AUTOSAR XML (schema 00046)
package /MICROSAR/Dcm_swc
  4 x mode declaration group, all with category=EXPLICIT_ORDER:
    DcmControlDtcSetting: initial-mode=ENABLEDTCSETTING, on-transition-value=2
      mode ENABLEDTCSETTING: value=0
      mode DISABLEDTCSETTING: value=1
    DcmEcuReset: initial-mode=NONE, on-transition-value=7
      7 x mode:
        NONE: value=0
        HARD: value=1
        KEYONOFF: value=2
        SOFT: value=3
        JUMPTOBOOTLOADER: value=4
        JUMPTOSYSSUPPLIERBOOTLOADER: value=5
        EXECUTE: value=6
    DcmDiagnosticSessionControl: initial-mode=DEFAULT_SESSION, on-transition-value=255
      mode DEFAULT_SESSION: value=1
      mode PROGRAMMING_SESSION: value=2
      mode EXTENDED_SESSION: value=3
    DcmCommunicationControl: initial-mode=DCM_ENABLE_RX_TX_NORM, on-transition-value=12
      12 x mode:
        DCM_ENABLE_RX_TX_NORM: value=0
        DCM_ENABLE_RX_DISABLE_TX_NORM: value=1
        DCM_DISABLE_RX_ENABLE_TX_NORM: value=2
        DCM_DISABLE_RX_TX_NORMAL: value=3
        DCM_ENABLE_RX_TX_NM: value=4
        DCM_ENABLE_RX_DISABLE_TX_NM: value=5
        DCM_DISABLE_RX_ENABLE_TX_NM: value=6
        DCM_DISABLE_RX_TX_NM: value=7
        DCM_ENABLE_RX_TX_NORM_NM: value=8
        DCM_ENABLE_RX_DISABLE_TX_NORM_NM: value=9
        DCM_DISABLE_RX_ENABLE_TX_NORM_NM: value=10
        DCM_DISABLE_RX_TX_NORM_NM: value=11
  data type mapping set DcmMappingSet  # Contains mapping for ModeDeclarationGroups which are provided by Dcm.
    mode-request-type-maps:
      implementation-data-type=Dcm_ControlDtcSettingType, mode-group=DcmControlDtcSetting
      implementation-data-type=Dcm_EcuResetType, mode-group=DcmEcuReset
      implementation-data-type=Dcm_DiagnosticSessionControlType, mode-group=DcmDiagnosticSessionControl
      implementation-data-type=Dcm_CommunicationModeType, mode-group=DcmCommunicationControl
package /MICROSAR/Dcm_swc/DataTypes
  18 x impl type:
    Dcm_ConfirmationStatusType: compu {0=DCM_RES_POS_OK, 1=DCM_RES_POS_NOT_OK, 2=DCM_RES_NEG_OK, 3=DCM_RES_NEG_NOT_OK}, range raw 0..3, implementation-data-type=uint8
    Dcm_OpStatusType: compu {0=DCM_INITIAL, 1=DCM_PENDING, 2=DCM_CANCEL, 3=DCM_FORCE_RCRRP_OK, 64=DCM_FORCE_RCRRP_NOT_OK}, range raw 0..64, implementation-data-type=uint8
    Dcm_NegativeResponseCodeType:
      compu {0=DCM_E_POSITIVERESPONSE, 16=DCM_E_GENERALREJECT, 17=DCM_E_SERVICENOTSUPPORTED, 18=DCM_E_SUBFUNCTIONNOTSUPPORTED, 19=DCM_E_INCORRECTMESSAGELENGTHORINVALIDFORMAT, 20=DCM_E_RESPONSETOOLONG, 33=DCM_E_BUSYREPEATREQUEST, 34=DCM_E_CONDITIONSNOTCORRECT, 36=DCM_E_REQUESTSEQUENCEERROR, 37=DCM_E_NORESPONSEFROMSUBNETCOMPONENT, 38=DCM_E_FAILUREPREVENTSEXECUTIONOFREQUESTEDACTION, 49=DCM_E_REQUESTOUTOFRANGE, 51=DCM_E_SECURITYACCESSDENIED, 53=DCM_E_INVALIDKEY, 54=DCM_E_EXCEEDNUMBEROFATTEMPTS, 55=DCM_E_REQUIREDTIMEDELAYNOTEXPIRED, 112=DCM_E_UPLOADDOWNLOADNOTACCEPTED, 113=DCM_E_TRANSFERDATASUSPENDED, 114=DCM_E_GENERALPROGRAMMINGFAILURE, 115=DCM_E_WRONGBLOCKSEQUENCECOUNTER, 120=DCM_E_REQUESTCORRECTLYRECEIVEDRESPONSEPENDING, 126=DCM_E_SUBFUNCTIONNOTSUPPORTEDINACTIVESESSION, 127=DCM_E_SERVICENOTSUPPORTEDINACTIVESESSION, 129=DCM_E_RPMTOOHIGH, 130=DCM_E_RPMTOOLOW, 131=DCM_E_ENGINEISRUNNING, 132=DCM_E_ENGINEISNOTRUNNING, 133=DCM_E_ENGINERUNTIMETOOLOW, 134=DCM_E_TEMPERATURETOOHIGH, 135=DCM_E_TEMPERATURETOOLOW, 136=DCM_E_VEHICLESPEEDTOOHIGH, 137=DCM_E_VEHICLESPEEDTOOLOW, 138=DCM_E_THROTTLE_PEDALTOOHIGH, 139=DCM_E_THROTTLE_PEDALTOOLOW, 140=DCM_E_TRANSMISSIONRANGENOTINNEUTRAL, 141=DCM_E_TRANSMISSIONRANGENOTINGEAR, 143=DCM_E_BRAKESWITCH_NOTCLOSED, 144=DCM_E_SHIFTERLEVERNOTINPARK, 145=DCM_E_TORQUECONVERTERCLUTCHLOCKED, 146=DCM_E_VOLTAGETOOHIGH, 147=DCM_E_VOLTAGETOOLOW, 240..249=DCM_E_VMSCNC_0..DCM_E_VMSCNC_9, 250=DCM_E_VMSCNC_A, 251=DCM_E_VMSCNC_B, 252=DCM_E_VMSCNC_C, 253=DCM_E_VMSCNC_D, 254=DCM_E_VMSCNC_E}
      range raw 0..254
      implementation-data-type=uint8
    Dcm_ProtocolType: compu {0=DCM_OBD_ON_CAN, 1=DCM_OBD_ON_FLEXRAY, 2=DCM_OBD_ON_IP, 3=DCM_UDS_ON_CAN, 4=DCM_UDS_ON_FLEXRAY, 5=DCM_UDS_ON_IP, 12=DCM_NO_ACTIVE_PROTOCOL, 240..254=DCM_SUPPLIER_1..DCM_SUPPLIER_15}, range raw 0..254, implementation-data-type=uint8
    Dcm_RequestKindType: compu {0=DCM_REQ_KIND_NONE, 1=DCM_REQ_KIND_EXTERNAL, 2=DCM_REQ_KIND_ROE}, range raw 0..2, implementation-data-type=uint8
    Dcm_SesCtrlType: compu {1=DCM_DEFAULT_SESSION, 2=DCM_PROGRAMMING_SESSION, 3=DCM_EXTENDED_DIAGNOSTIC_SESSION}, range raw 0..3, implementation-data-type=uint8
    Dcm_ControlDtcSettingType: compu {0=DCM_ENUM_ENABLEDTCSETTING, 1=DCM_ENUM_DISABLEDTCSETTING}, range raw 0..255, implementation-data-type=uint8
    Dcm_EcuResetType: compu {0=DCM_ENUM_NONE, 1=DCM_ENUM_HARD, 2=DCM_ENUM_KEYONOFF, 3=DCM_ENUM_SOFT, 4=DCM_ENUM_JUMPTOBOOTLOADER, 5=DCM_ENUM_JUMPTOSYSSUPPLIERBOOTLOADER, 6=DCM_ENUM_EXECUTE}, range raw 0..255, implementation-data-type=uint8
    Dcm_DiagnosticSessionControlType: compu {1=DCM_ENUM_DEFAULT_SESSION, 2=DCM_ENUM_PROGRAMMING_SESSION, 3=DCM_ENUM_EXTENDED_SESSION}, range raw 0..255, implementation-data-type=uint8
    Dcm_CommunicationModeType:
      compu {0=DCM_ENABLE_RX_TX_NORM, 1=DCM_ENABLE_RX_DISABLE_TX_NORM, 2=DCM_DISABLE_RX_ENABLE_TX_NORM, 3=DCM_DISABLE_RX_TX_NORMAL, 4=DCM_ENABLE_RX_TX_NM, 5=DCM_ENABLE_RX_DISABLE_TX_NM, 6=DCM_DISABLE_RX_ENABLE_TX_NM, 7=DCM_DISABLE_RX_TX_NM, 8=DCM_ENABLE_RX_TX_NORM_NM, 9=DCM_ENABLE_RX_DISABLE_TX_NORM_NM, 10=DCM_DISABLE_RX_ENABLE_TX_NORM_NM, 11=DCM_DISABLE_RX_TX_NORM_NM}
      range raw 0..255
      implementation-data-type=uint8
    Dcm_Data1ByteType: category=ARRAY, sw-calibration-access=READ-ONLY
      element Dcm_Data1ByteTypeElement: array-size=1, array-size-semantics=FIXED-SIZE, implementation-data-type=uint8
    Dcm_SecLevelType: compu {0=DCM_SEC_LEV_LOCKED, 1=DCM_SEC_LEV_L1}, range raw 0..1, implementation-data-type=uint8
    Dcm_Data4ByteType: category=ARRAY, sw-calibration-access=READ-ONLY
      element Dcm_Data4ByteTypeElement: array-size=4, array-size-semantics=FIXED-SIZE, implementation-data-type=uint8
    Dcm_Data2ByteType: category=ARRAY, sw-calibration-access=READ-ONLY
      element Dcm_Data2ByteTypeElement: array-size=2, array-size-semantics=FIXED-SIZE, implementation-data-type=uint8
    Dcm_Data13ByteType: category=ARRAY, sw-calibration-access=READ-ONLY
      element Dcm_Data13ByteTypeElement: array-size=13, array-size-semantics=FIXED-SIZE, implementation-data-type=uint8
    Dcm_Data17ByteType: category=ARRAY, sw-calibration-access=READ-ONLY
      element Dcm_Data17ByteTypeElement: array-size=17, array-size-semantics=FIXED-SIZE, implementation-data-type=uint8
    Dcm_Data5ByteType: category=ARRAY, sw-calibration-access=READ-ONLY
      element Dcm_Data5ByteTypeElement: array-size=5, array-size-semantics=FIXED-SIZE, implementation-data-type=uint8
    Dcm_Data8ByteType: category=ARRAY, sw-calibration-access=READ-ONLY
      element Dcm_Data8ByteTypeElement: array-size=8, array-size-semantics=FIXED-SIZE, implementation-data-type=uint8
package /MICROSAR/Dcm_swc/Interfaces
  mode switch interface DcmControlDtcSetting: is-service=true, service-kind=DIAGNOSTIC-COMMUNICATION-MANAGER
    mode group DcmControlDtcSetting: type=DcmControlDtcSetting
  mode switch interface DcmEcuReset: is-service=true, service-kind=DIAGNOSTIC-COMMUNICATION-MANAGER
    mode group DcmEcuReset: type=DcmEcuReset
  mode switch interface DcmDiagnosticSessionControl: is-service=true, service-kind=DIAGNOSTIC-COMMUNICATION-MANAGER
    mode group DcmDiagnosticSessionControl: type=DcmDiagnosticSessionControl
  client server interface DCMServices: is-service=true, service-kind=DIAGNOSTIC-COMMUNICATION-MANAGER
    6 x operation:
      GetActiveProtocol: possible-error=E_OK
        arg ActiveProtocol: type=Dcm_ProtocolType, direction=OUT
      GetSesCtrlType: possible-error=E_OK
        arg SesCtrlType: type=Dcm_SesCtrlType, direction=OUT
      ResetToDefaultSession: possible-error=E_OK
      SetActiveDiagnostic: possible-error=E_OK
        arg active: type=boolean, direction=IN
      GetRequestKind: possible-error=DCMServices/E_NOT_OK
        arg TesterSourceAddress: type=uint16, direction=IN
        arg RequestKind: type=Dcm_RequestKindType, direction=OUT
      GetSecurityLevel: possible-error=E_OK
        arg SecLevel: type=Dcm_SecLevelType, direction=OUT
    error E_OK: error-code=0
    error E_NOT_OK: error-code=1
  client server interface RoutineServices_ECU_Check: is-service=true, service-kind=DIAGNOSTIC-COMMUNICATION-MANAGER
    operation Start: possible-error=[RoutineServices_ECU_Check/E_NOT_OK, RoutineServices_ECU_Check/DCM_E_PENDING, DCM_E_FORCE_RCRRP]
      4 x arg:
        In_Start_ECU_Check: type=uint8, direction=IN
        OpStatus: type=Dcm_OpStatusType, direction=IN
        Out_ECU_Check_is_in_progress: type=uint8, direction=OUT
        ErrorCode: type=Dcm_NegativeResponseCodeType, direction=OUT
    operation RequestResults: possible-error=[RoutineServices_ECU_Check/E_NOT_OK, RoutineServices_ECU_Check/DCM_E_PENDING, DCM_E_FORCE_RCRRP]
      arg OpStatus: type=Dcm_OpStatusType, direction=IN
      arg Out_ECU_Check_status: type=uint8, direction=OUT
      arg ErrorCode: type=Dcm_NegativeResponseCodeType, direction=OUT
    error E_NOT_OK: error-code=1
    error DCM_E_PENDING: error-code=10
    error DCM_E_FORCE_RCRRP: error-code=12
  client server interface DataServices_Braking_Brake_Pedal: is-service=true, service-kind=DIAGNOSTIC-COMMUNICATION-MANAGER
    operation ReadData: possible-error=[DataServices_Braking_Brake_Pedal/E_NOT_OK, DataServices_Braking_Brake_Pedal/DCM_E_PENDING]
      arg OpStatus: type=Dcm_OpStatusType, direction=IN
      arg Data: type=Dcm_Data1ByteType, direction=OUT
    operation ConditionCheckRead: possible-error=[DataServices_Braking_Brake_Pedal/E_NOT_OK, DataServices_Braking_Brake_Pedal/DCM_E_PENDING]
      arg OpStatus: type=Dcm_OpStatusType, direction=IN
      arg ErrorCode: type=Dcm_NegativeResponseCodeType, direction=OUT
    error E_NOT_OK: error-code=1
    error DCM_E_PENDING: error-code=10
  mode switch interface DcmCommunicationControl_ComMConf_ComMChannel_CN_DBCNetWork_05d62413: is-service=true, service-kind=DIAGNOSTIC-COMMUNICATION-MANAGER
    mode group DcmCommunicationControl_ComMConf_ComMChannel_CN_DBCNetWork_05d62413: type=DcmCommunicationControl
  58 x client server interface, all with is-service=true, service-kind=DIAGNOSTIC-COMMUNICATION-MANAGER:
    SecurityAccess_UnlockedL1
      operation GetSeed: possible-error=[SecurityAccess_UnlockedL1/E_NOT_OK, SecurityAccess_UnlockedL1/DCM_E_PENDING]
        arg OpStatus: type=Dcm_OpStatusType, direction=IN
        arg Seed: type=Dcm_Data4ByteType, direction=OUT
        arg ErrorCode: type=Dcm_NegativeResponseCodeType, direction=OUT
      operation CompareKey: possible-error=[SecurityAccess_UnlockedL1/E_NOT_OK, SecurityAccess_UnlockedL1/DCM_E_PENDING, DCM_E_COMPARE_KEY_FAILED]
        arg Key: type=Dcm_Data4ByteType, direction=IN
        arg OpStatus: type=Dcm_OpStatusType, direction=IN
        arg ErrorCode: type=Dcm_NegativeResponseCodeType, direction=OUT
      error E_NOT_OK: error-code=1
      error DCM_E_PENDING: error-code=10
      error DCM_E_COMPARE_KEY_FAILED: error-code=11
    DataServices_Braking_Valve_Status_RR
      operation ReadData: possible-error=[DataServices_Braking_Valve_Status_RR/E_NOT_OK, DataServices_Braking_Valve_Status_RR/DCM_E_PENDING]
        arg OpStatus: type=Dcm_OpStatusType, direction=IN
        arg Data: type=Dcm_Data1ByteType, direction=OUT
      operation ConditionCheckRead: possible-error=[DataServices_Braking_Valve_Status_RR/E_NOT_OK, DataServices_Braking_Valve_Status_RR/DCM_E_PENDING]
        arg OpStatus: type=Dcm_OpStatusType, direction=IN
        arg ErrorCode: type=Dcm_NegativeResponseCodeType, direction=OUT
      error E_NOT_OK: error-code=1
      error DCM_E_PENDING: error-code=10
    DataServices_Braking_Valve_Status_FR
      operation ReadData: possible-error=[DataServices_Braking_Valve_Status_FR/E_NOT_OK, DataServices_Braking_Valve_Status_FR/DCM_E_PENDING]
        arg OpStatus: type=Dcm_OpStatusType, direction=IN
        arg Data: type=Dcm_Data1ByteType, direction=OUT
      operation ConditionCheckRead: possible-error=[DataServices_Braking_Valve_Status_FR/E_NOT_OK, DataServices_Braking_Valve_Status_FR/DCM_E_PENDING]
        arg OpStatus: type=Dcm_OpStatusType, direction=IN
        arg ErrorCode: type=Dcm_NegativeResponseCodeType, direction=OUT
      error E_NOT_OK: error-code=1
      error DCM_E_PENDING: error-code=10
    DataServices_Braking_Status_Hydraulic_Pump
      operation ReadData: possible-error=[DataServices_Braking_Status_Hydraulic_Pump/E_NOT_OK, DataServices_Braking_Status_Hydraulic_Pump/DCM_E_PENDING]
        arg OpStatus: type=Dcm_OpStatusType, direction=IN
        arg Data: type=Dcm_Data1ByteType, direction=OUT
      operation ConditionCheckRead: possible-error=[DataServices_Braking_Status_Hydraulic_Pump/E_NOT_OK, DataServices_Braking_Status_Hydraulic_Pump/DCM_E_PENDING]
        arg OpStatus: type=Dcm_OpStatusType, direction=IN
        arg ErrorCode: type=Dcm_NegativeResponseCodeType, direction=OUT
      error E_NOT_OK: error-code=1
      error DCM_E_PENDING: error-code=10
    DataServices_Braking_Brake_Pressure
      operation ReadData: possible-error=[DataServices_Braking_Brake_Pressure/E_NOT_OK, DataServices_Braking_Brake_Pressure/DCM_E_PENDING]
        arg OpStatus: type=Dcm_OpStatusType, direction=IN
        arg Data: type=Dcm_Data1ByteType, direction=OUT
      operation ConditionCheckRead: possible-error=[DataServices_Braking_Brake_Pressure/E_NOT_OK, DataServices_Braking_Brake_Pressure/DCM_E_PENDING]
        arg OpStatus: type=Dcm_OpStatusType, direction=IN
        arg ErrorCode: type=Dcm_NegativeResponseCodeType, direction=OUT
      error E_NOT_OK: error-code=1
      error DCM_E_PENDING: error-code=10
    DataServices_Braking_Valve_Status_RL
      operation ReadData: possible-error=[DataServices_Braking_Valve_Status_RL/E_NOT_OK, DataServices_Braking_Valve_Status_RL/DCM_E_PENDING]
        arg OpStatus: type=Dcm_OpStatusType, direction=IN
        arg Data: type=Dcm_Data1ByteType, direction=OUT
      operation ConditionCheckRead: possible-error=[DataServices_Braking_Valve_Status_RL/E_NOT_OK, DataServices_Braking_Valve_Status_RL/DCM_E_PENDING]
        arg OpStatus: type=Dcm_OpStatusType, direction=IN
        arg ErrorCode: type=Dcm_NegativeResponseCodeType, direction=OUT
      error E_NOT_OK: error-code=1
      error DCM_E_PENDING: error-code=10
    DataServices_Braking_Valve_Status_FL
      operation ReadData: possible-error=[DataServices_Braking_Valve_Status_FL/E_NOT_OK, DataServices_Braking_Valve_Status_FL/DCM_E_PENDING]
        arg OpStatus: type=Dcm_OpStatusType, direction=IN
        arg Data: type=Dcm_Data1ByteType, direction=OUT
      operation ConditionCheckRead: possible-error=[DataServices_Braking_Valve_Status_FL/E_NOT_OK, DataServices_Braking_Valve_Status_FL/DCM_E_PENDING]
        arg OpStatus: type=Dcm_OpStatusType, direction=IN
        arg ErrorCode: type=Dcm_NegativeResponseCodeType, direction=OUT
      error E_NOT_OK: error-code=1
      error DCM_E_PENDING: error-code=10
    DataServices_Hydro_Unit_Valve_Status_RR
      operation ReadData: possible-error=[DataServices_Hydro_Unit_Valve_Status_RR/E_NOT_OK, DataServices_Hydro_Unit_Valve_Status_RR/DCM_E_PENDING]
        arg OpStatus: type=Dcm_OpStatusType, direction=IN
        arg Data: type=Dcm_Data1ByteType, direction=OUT
      operation ConditionCheckRead: possible-error=[DataServices_Hydro_Unit_Valve_Status_RR/E_NOT_OK, DataServices_Hydro_Unit_Valve_Status_RR/DCM_E_PENDING]
        arg OpStatus: type=Dcm_OpStatusType, direction=IN
        arg ErrorCode: type=Dcm_NegativeResponseCodeType, direction=OUT
      error E_NOT_OK: error-code=1
      error DCM_E_PENDING: error-code=10
    DataServices_Hydro_Unit_Valve_Voltage_FR
      operation ReadData: possible-error=[DataServices_Hydro_Unit_Valve_Voltage_FR/E_NOT_OK, DataServices_Hydro_Unit_Valve_Voltage_FR/DCM_E_PENDING]
        arg OpStatus: type=Dcm_OpStatusType, direction=IN
        arg Data: type=Dcm_Data1ByteType, direction=OUT
      operation ConditionCheckRead: possible-error=[DataServices_Hydro_Unit_Valve_Voltage_FR/E_NOT_OK, DataServices_Hydro_Unit_Valve_Voltage_FR/DCM_E_PENDING]
        arg OpStatus: type=Dcm_OpStatusType, direction=IN
        arg ErrorCode: type=Dcm_NegativeResponseCodeType, direction=OUT
      error E_NOT_OK: error-code=1
      error DCM_E_PENDING: error-code=10
    DataServices_Hydro_Unit_Valve_Status_FR
      operation ReadData: possible-error=[DataServices_Hydro_Unit_Valve_Status_FR/E_NOT_OK, DataServices_Hydro_Unit_Valve_Status_FR/DCM_E_PENDING]
        arg OpStatus: type=Dcm_OpStatusType, direction=IN
        arg Data: type=Dcm_Data1ByteType, direction=OUT
      operation ConditionCheckRead: possible-error=[DataServices_Hydro_Unit_Valve_Status_FR/E_NOT_OK, DataServices_Hydro_Unit_Valve_Status_FR/DCM_E_PENDING]
        arg OpStatus: type=Dcm_OpStatusType, direction=IN
        arg ErrorCode: type=Dcm_NegativeResponseCodeType, direction=OUT
      error E_NOT_OK: error-code=1
      error DCM_E_PENDING: error-code=10
    DataServices_Hydro_Unit_Valve_Voltage_RL
      operation ReadData: possible-error=[DataServices_Hydro_Unit_Valve_Voltage_RL/E_NOT_OK, DataServices_Hydro_Unit_Valve_Voltage_RL/DCM_E_PENDING]
        arg OpStatus: type=Dcm_OpStatusType, direction=IN
        arg Data: type=Dcm_Data1ByteType, direction=OUT
      operation ConditionCheckRead: possible-error=[DataServices_Hydro_Unit_Valve_Voltage_RL/E_NOT_OK, DataServices_Hydro_Unit_Valve_Voltage_RL/DCM_E_PENDING]
        arg OpStatus: type=Dcm_OpStatusType, direction=IN
        arg ErrorCode: type=Dcm_NegativeResponseCodeType, direction=OUT
      error E_NOT_OK: error-code=1
      error DCM_E_PENDING: error-code=10
    DataServices_Hydro_Unit_Valve_Status_RL
      operation ReadData: possible-error=[DataServices_Hydro_Unit_Valve_Status_RL/E_NOT_OK, DataServices_Hydro_Unit_Valve_Status_RL/DCM_E_PENDING]
        arg OpStatus: type=Dcm_OpStatusType, direction=IN
        arg Data: type=Dcm_Data1ByteType, direction=OUT
      operation ConditionCheckRead: possible-error=[DataServices_Hydro_Unit_Valve_Status_RL/E_NOT_OK, DataServices_Hydro_Unit_Valve_Status_RL/DCM_E_PENDING]
        arg OpStatus: type=Dcm_OpStatusType, direction=IN
        arg ErrorCode: type=Dcm_NegativeResponseCodeType, direction=OUT
      error E_NOT_OK: error-code=1
      error DCM_E_PENDING: error-code=10
    DataServices_Hydro_Unit_Valve_Voltage_FL
      operation ReadData: possible-error=[DataServices_Hydro_Unit_Valve_Voltage_FL/E_NOT_OK, DataServices_Hydro_Unit_Valve_Voltage_FL/DCM_E_PENDING]
        arg OpStatus: type=Dcm_OpStatusType, direction=IN
        arg Data: type=Dcm_Data1ByteType, direction=OUT
      operation ConditionCheckRead: possible-error=[DataServices_Hydro_Unit_Valve_Voltage_FL/E_NOT_OK, DataServices_Hydro_Unit_Valve_Voltage_FL/DCM_E_PENDING]
        arg OpStatus: type=Dcm_OpStatusType, direction=IN
        arg ErrorCode: type=Dcm_NegativeResponseCodeType, direction=OUT
      error E_NOT_OK: error-code=1
      error DCM_E_PENDING: error-code=10
    DataServices_Hydro_Unit_Valve_Voltage_RR
      operation ReadData: possible-error=[DataServices_Hydro_Unit_Valve_Voltage_RR/E_NOT_OK, DataServices_Hydro_Unit_Valve_Voltage_RR/DCM_E_PENDING]
        arg OpStatus: type=Dcm_OpStatusType, direction=IN
        arg Data: type=Dcm_Data1ByteType, direction=OUT
      operation ConditionCheckRead: possible-error=[DataServices_Hydro_Unit_Valve_Voltage_RR/E_NOT_OK, DataServices_Hydro_Unit_Valve_Voltage_RR/DCM_E_PENDING]
        arg OpStatus: type=Dcm_OpStatusType, direction=IN
        arg ErrorCode: type=Dcm_NegativeResponseCodeType, direction=OUT
      error E_NOT_OK: error-code=1
      error DCM_E_PENDING: error-code=10
    DataServices_Hydro_Unit_Valve_Status_FL
      operation ReadData: possible-error=[DataServices_Hydro_Unit_Valve_Status_FL/E_NOT_OK, DataServices_Hydro_Unit_Valve_Status_FL/DCM_E_PENDING]
        arg OpStatus: type=Dcm_OpStatusType, direction=IN
        arg Data: type=Dcm_Data1ByteType, direction=OUT
      operation ConditionCheckRead: possible-error=[DataServices_Hydro_Unit_Valve_Status_FL/E_NOT_OK, DataServices_Hydro_Unit_Valve_Status_FL/DCM_E_PENDING]
        arg OpStatus: type=Dcm_OpStatusType, direction=IN
        arg ErrorCode: type=Dcm_NegativeResponseCodeType, direction=OUT
      error E_NOT_OK: error-code=1
      error DCM_E_PENDING: error-code=10
    DataServices_Switches_Brake_Switch
      operation ReadData: possible-error=[DataServices_Switches_Brake_Switch/E_NOT_OK, DataServices_Switches_Brake_Switch/DCM_E_PENDING]
        arg OpStatus: type=Dcm_OpStatusType, direction=IN
        arg Data: type=Dcm_Data1ByteType, direction=OUT
      operation ResetToDefault: possible-error=[DataServices_Switches_Brake_Switch/E_NOT_OK, DataServices_Switches_Brake_Switch/DCM_E_PENDING]
        arg OpStatus: type=Dcm_OpStatusType, direction=IN
        arg ErrorCode: type=Dcm_NegativeResponseCodeType, direction=OUT
      operation ShortTermAdjustment: possible-error=[DataServices_Switches_Brake_Switch/E_NOT_OK, DataServices_Switches_Brake_Switch/DCM_E_PENDING]
        arg Data: type=Dcm_Data1ByteType, direction=IN
        arg OpStatus: type=Dcm_OpStatusType, direction=IN
        arg ErrorCode: type=Dcm_NegativeResponseCodeType, direction=OUT
      error E_NOT_OK: error-code=1
      error DCM_E_PENDING: error-code=10
    DataServices_Switches_Parking_Brake_Switch
      operation ReadData: possible-error=[DataServices_Switches_Parking_Brake_Switch/E_NOT_OK, DataServices_Switches_Parking_Brake_Switch/DCM_E_PENDING]
        arg OpStatus: type=Dcm_OpStatusType, direction=IN
        arg Data: type=Dcm_Data1ByteType, direction=OUT
      operation ResetToDefault: possible-error=[DataServices_Switches_Parking_Brake_Switch/E_NOT_OK, DataServices_Switches_Parking_Brake_Switch/DCM_E_PENDING]
        arg OpStatus: type=Dcm_OpStatusType, direction=IN
        arg ErrorCode: type=Dcm_NegativeResponseCodeType, direction=OUT
      operation ShortTermAdjustment: possible-error=[DataServices_Switches_Parking_Brake_Switch/E_NOT_OK, DataServices_Switches_Parking_Brake_Switch/DCM_E_PENDING]
        arg Data: type=Dcm_Data1ByteType, direction=IN
        arg OpStatus: type=Dcm_OpStatusType, direction=IN
        arg ErrorCode: type=Dcm_NegativeResponseCodeType, direction=OUT
      error E_NOT_OK: error-code=1
      error DCM_E_PENDING: error-code=10
    DataServices_Switches_Rear_Gear_Switch
      operation ReadData: possible-error=[DataServices_Switches_Rear_Gear_Switch/E_NOT_OK, DataServices_Switches_Rear_Gear_Switch/DCM_E_PENDING]
        arg OpStatus: type=Dcm_OpStatusType, direction=IN
        arg Data: type=Dcm_Data1ByteType, direction=OUT
      operation ResetToDefault: possible-error=[DataServices_Switches_Rear_Gear_Switch/E_NOT_OK, DataServices_Switches_Rear_Gear_Switch/DCM_E_PENDING]
        arg OpStatus: type=Dcm_OpStatusType, direction=IN
        arg ErrorCode: type=Dcm_NegativeResponseCodeType, direction=OUT
      operation ShortTermAdjustment: possible-error=[DataServices_Switches_Rear_Gear_Switch/E_NOT_OK, DataServices_Switches_Rear_Gear_Switch/DCM_E_PENDING]
        arg Data: type=Dcm_Data1ByteType, direction=IN
        arg OpStatus: type=Dcm_OpStatusType, direction=IN
        arg ErrorCode: type=Dcm_NegativeResponseCodeType, direction=OUT
      error E_NOT_OK: error-code=1
      error DCM_E_PENDING: error-code=10
    DataServices_Service_Information_Remaining_Service_Brake_Fluid_Life
      operation ReadData: possible-error=[DataServices_Service_Information_Remaining_Service_Brake_Fluid_Life/E_NOT_OK, DataServices_Service_Information_Remaining_Service_Brake_Fluid_Life/DCM_E_PENDING]
        arg OpStatus: type=Dcm_OpStatusType, direction=IN
        arg Data: type=Dcm_Data1ByteType, direction=OUT
      operation ConditionCheckRead: possible-error=[DataServices_Service_Information_Remaining_Service_Brake_Fluid_Life/E_NOT_OK, DataServices_Service_Information_Remaining_Service_Brake_Fluid_Life/DCM_E_PENDING]
        arg OpStatus: type=Dcm_OpStatusType, direction=IN
        arg ErrorCode: type=Dcm_NegativeResponseCodeType, direction=OUT
      operation WriteData: possible-error=[DataServices_Service_Information_Remaining_Service_Brake_Fluid_Life/E_NOT_OK, DataServices_Service_Information_Remaining_Service_Brake_Fluid_Life/DCM_E_PENDING]
        arg Data: type=Dcm_Data1ByteType, direction=IN
        arg OpStatus: type=Dcm_OpStatusType, direction=IN
        arg ErrorCode: type=Dcm_NegativeResponseCodeType, direction=OUT
      error E_NOT_OK: error-code=1
      error DCM_E_PENDING: error-code=10
    DataServices_Service_Information_Remaining_Service_Time_Left
      operation ReadData: possible-error=[DataServices_Service_Information_Remaining_Service_Time_Left/E_NOT_OK, DataServices_Service_Information_Remaining_Service_Time_Left/DCM_E_PENDING]
        arg OpStatus: type=Dcm_OpStatusType, direction=IN
        arg Data: type=Dcm_Data2ByteType, direction=OUT
      operation ConditionCheckRead: possible-error=[DataServices_Service_Information_Remaining_Service_Time_Left/E_NOT_OK, DataServices_Service_Information_Remaining_Service_Time_Left/DCM_E_PENDING]
        arg OpStatus: type=Dcm_OpStatusType, direction=IN
        arg ErrorCode: type=Dcm_NegativeResponseCodeType, direction=OUT
      operation WriteData: possible-error=[DataServices_Service_Information_Remaining_Service_Time_Left/E_NOT_OK, DataServices_Service_Information_Remaining_Service_Time_Left/DCM_E_PENDING]
        arg Data: type=Dcm_Data2ByteType, direction=IN
        arg OpStatus: type=Dcm_OpStatusType, direction=IN
        arg ErrorCode: type=Dcm_NegativeResponseCodeType, direction=OUT
      error E_NOT_OK: error-code=1
      error DCM_E_PENDING: error-code=10
    DataServices_Hydraulic_Pump_Status_Hydraulic_Pump
      operation ReadData: possible-error=[DataServices_Hydraulic_Pump_Status_Hydraulic_Pump/E_NOT_OK, DataServices_Hydraulic_Pump_Status_Hydraulic_Pump/DCM_E_PENDING]
        arg OpStatus: type=Dcm_OpStatusType, direction=IN
        arg Data: type=Dcm_Data1ByteType, direction=OUT
      operation ConditionCheckRead: possible-error=[DataServices_Hydraulic_Pump_Status_Hydraulic_Pump/E_NOT_OK, DataServices_Hydraulic_Pump_Status_Hydraulic_Pump/DCM_E_PENDING]
        arg OpStatus: type=Dcm_OpStatusType, direction=IN
        arg ErrorCode: type=Dcm_NegativeResponseCodeType, direction=OUT
      error E_NOT_OK: error-code=1
      error DCM_E_PENDING: error-code=10
    DataServices_Hydraulic_Pump_Hydraulic_Pump_Voltage
      operation ReadData: possible-error=[DataServices_Hydraulic_Pump_Hydraulic_Pump_Voltage/E_NOT_OK, DataServices_Hydraulic_Pump_Hydraulic_Pump_Voltage/DCM_E_PENDING]
        arg OpStatus: type=Dcm_OpStatusType, direction=IN
        arg Data: type=Dcm_Data1ByteType, direction=OUT
      operation ConditionCheckRead: possible-error=[DataServices_Hydraulic_Pump_Hydraulic_Pump_Voltage/E_NOT_OK, DataServices_Hydraulic_Pump_Hydraulic_Pump_Voltage/DCM_E_PENDING]
        arg OpStatus: type=Dcm_OpStatusType, direction=IN
        arg ErrorCode: type=Dcm_NegativeResponseCodeType, direction=OUT
      error E_NOT_OK: error-code=1
      error DCM_E_PENDING: error-code=10
    DataServices_Hydraulic_Pump_Hydraulic_Pump_Performance
      operation ReadData: possible-error=[DataServices_Hydraulic_Pump_Hydraulic_Pump_Performance/E_NOT_OK, DataServices_Hydraulic_Pump_Hydraulic_Pump_Performance/DCM_E_PENDING]
        arg OpStatus: type=Dcm_OpStatusType, direction=IN
        arg Data: type=Dcm_Data1ByteType, direction=OUT
      operation ConditionCheckRead: possible-error=[DataServices_Hydraulic_Pump_Hydraulic_Pump_Performance/E_NOT_OK, DataServices_Hydraulic_Pump_Hydraulic_Pump_Performance/DCM_E_PENDING]
        arg OpStatus: type=Dcm_OpStatusType, direction=IN
        arg ErrorCode: type=Dcm_NegativeResponseCodeType, direction=OUT
      error E_NOT_OK: error-code=1
      error DCM_E_PENDING: error-code=10
    DataServices_Wheel_Type_Wheel_type
      operation ReadData: possible-error=[DataServices_Wheel_Type_Wheel_type/E_NOT_OK, DataServices_Wheel_Type_Wheel_type/DCM_E_PENDING]
        arg OpStatus: type=Dcm_OpStatusType, direction=IN
        arg Data: type=Dcm_Data1ByteType, direction=OUT
      operation ConditionCheckRead: possible-error=[DataServices_Wheel_Type_Wheel_type/E_NOT_OK, DataServices_Wheel_Type_Wheel_type/DCM_E_PENDING]
        arg OpStatus: type=Dcm_OpStatusType, direction=IN
        arg ErrorCode: type=Dcm_NegativeResponseCodeType, direction=OUT
      operation WriteData: possible-error=[DataServices_Wheel_Type_Wheel_type/E_NOT_OK, DataServices_Wheel_Type_Wheel_type/DCM_E_PENDING]
        arg Data: type=Dcm_Data1ByteType, direction=IN
        arg OpStatus: type=Dcm_OpStatusType, direction=IN
        arg ErrorCode: type=Dcm_NegativeResponseCodeType, direction=OUT
      error E_NOT_OK: error-code=1
      error DCM_E_PENDING: error-code=10
    DataServices_Hardware_Supplier_Identification_HardwareSupplier
      operation ReadData: possible-error=[DataServices_Hardware_Supplier_Identification_HardwareSupplier/E_NOT_OK, DataServices_Hardware_Supplier_Identification_HardwareSupplier/DCM_E_PENDING]
        arg OpStatus: type=Dcm_OpStatusType, direction=IN
        arg Data: type=Dcm_Data1ByteType, direction=OUT
      operation ConditionCheckRead: possible-error=[DataServices_Hardware_Supplier_Identification_HardwareSupplier/E_NOT_OK, DataServices_Hardware_Supplier_Identification_HardwareSupplier/DCM_E_PENDING]
        arg OpStatus: type=Dcm_OpStatusType, direction=IN
        arg ErrorCode: type=Dcm_NegativeResponseCodeType, direction=OUT
      operation WriteData: possible-error=[DataServices_Hardware_Supplier_Identification_HardwareSupplier/E_NOT_OK, DataServices_Hardware_Supplier_Identification_HardwareSupplier/DCM_E_PENDING]
        arg Data: type=Dcm_Data1ByteType, direction=IN
        arg OpStatus: type=Dcm_OpStatusType, direction=IN
        arg ErrorCode: type=Dcm_NegativeResponseCodeType, direction=OUT
      error E_NOT_OK: error-code=1
      error DCM_E_PENDING: error-code=10
    DataServices_Serial_Number_SerialNumber
      operation ReadData: possible-error=[DataServices_Serial_Number_SerialNumber/E_NOT_OK, DataServices_Serial_Number_SerialNumber/DCM_E_PENDING]
        arg OpStatus: type=Dcm_OpStatusType, direction=IN
        arg Data: type=Dcm_Data13ByteType, direction=OUT
      operation ConditionCheckRead: possible-error=[DataServices_Serial_Number_SerialNumber/E_NOT_OK, DataServices_Serial_Number_SerialNumber/DCM_E_PENDING]
        arg OpStatus: type=Dcm_OpStatusType, direction=IN
        arg ErrorCode: type=Dcm_NegativeResponseCodeType, direction=OUT
      operation WriteData: possible-error=[DataServices_Serial_Number_SerialNumber/E_NOT_OK, DataServices_Serial_Number_SerialNumber/DCM_E_PENDING]
        arg Data: type=Dcm_Data13ByteType, direction=IN
        arg OpStatus: type=Dcm_OpStatusType, direction=IN
        arg ErrorCode: type=Dcm_NegativeResponseCodeType, direction=OUT
      error E_NOT_OK: error-code=1
      error DCM_E_PENDING: error-code=10
    DataServices_VIN_VIN
      operation ReadData: possible-error=[DataServices_VIN_VIN/E_NOT_OK, DataServices_VIN_VIN/DCM_E_PENDING]
        arg OpStatus: type=Dcm_OpStatusType, direction=IN
        arg Data: type=Dcm_Data17ByteType, direction=OUT
      operation ConditionCheckRead: possible-error=[DataServices_VIN_VIN/E_NOT_OK, DataServices_VIN_VIN/DCM_E_PENDING]
        arg OpStatus: type=Dcm_OpStatusType, direction=IN
        arg ErrorCode: type=Dcm_NegativeResponseCodeType, direction=OUT
      operation WriteData: possible-error=[DataServices_VIN_VIN/E_NOT_OK, DataServices_VIN_VIN/DCM_E_PENDING]
        arg Data: type=Dcm_Data17ByteType, direction=IN
        arg OpStatus: type=Dcm_OpStatusType, direction=IN
        arg ErrorCode: type=Dcm_NegativeResponseCodeType, direction=OUT
      error E_NOT_OK: error-code=1
      error DCM_E_PENDING: error-code=10
    DataServices_Software_Version_SoftwareVersion
      operation ReadData: possible-error=[DataServices_Software_Version_SoftwareVersion/E_NOT_OK, DataServices_Software_Version_SoftwareVersion/DCM_E_PENDING]
        arg OpStatus: type=Dcm_OpStatusType, direction=IN
        arg Data: type=Dcm_Data5ByteType, direction=OUT
      operation ConditionCheckRead: possible-error=[DataServices_Software_Version_SoftwareVersion/E_NOT_OK, DataServices_Software_Version_SoftwareVersion/DCM_E_PENDING]
        arg OpStatus: type=Dcm_OpStatusType, direction=IN
        arg ErrorCode: type=Dcm_NegativeResponseCodeType, direction=OUT
      operation WriteData: possible-error=[DataServices_Software_Version_SoftwareVersion/E_NOT_OK, DataServices_Software_Version_SoftwareVersion/DCM_E_PENDING]
        arg Data: type=Dcm_Data5ByteType, direction=IN
        arg OpStatus: type=Dcm_OpStatusType, direction=IN
        arg ErrorCode: type=Dcm_NegativeResponseCodeType, direction=OUT
      error E_NOT_OK: error-code=1
      error DCM_E_PENDING: error-code=10
    DataServices_Wheel_Speed_Wheel_Speed_RR
      operation ReadData: possible-error=[DataServices_Wheel_Speed_Wheel_Speed_RR/E_NOT_OK, DataServices_Wheel_Speed_Wheel_Speed_RR/DCM_E_PENDING]
        arg OpStatus: type=Dcm_OpStatusType, direction=IN
        arg Data: type=Dcm_Data1ByteType, direction=OUT
      operation ConditionCheckRead: possible-error=[DataServices_Wheel_Speed_Wheel_Speed_RR/E_NOT_OK, DataServices_Wheel_Speed_Wheel_Speed_RR/DCM_E_PENDING]
        arg OpStatus: type=Dcm_OpStatusType, direction=IN
        arg ErrorCode: type=Dcm_NegativeResponseCodeType, direction=OUT
      error E_NOT_OK: error-code=1
      error DCM_E_PENDING: error-code=10
    DataServices_Wheel_Speed_Wheel_Voltage_RR
      operation ReadData: possible-error=[DataServices_Wheel_Speed_Wheel_Voltage_RR/E_NOT_OK, DataServices_Wheel_Speed_Wheel_Voltage_RR/DCM_E_PENDING]
        arg OpStatus: type=Dcm_OpStatusType, direction=IN
        arg Data: type=Dcm_Data1ByteType, direction=OUT
      operation ConditionCheckRead: possible-error=[DataServices_Wheel_Speed_Wheel_Voltage_RR/E_NOT_OK, DataServices_Wheel_Speed_Wheel_Voltage_RR/DCM_E_PENDING]
        arg OpStatus: type=Dcm_OpStatusType, direction=IN
        arg ErrorCode: type=Dcm_NegativeResponseCodeType, direction=OUT
      error E_NOT_OK: error-code=1
      error DCM_E_PENDING: error-code=10
    DataServices_Wheel_Speed_Wheel_Speed_FR
      operation ReadData: possible-error=[DataServices_Wheel_Speed_Wheel_Speed_FR/E_NOT_OK, DataServices_Wheel_Speed_Wheel_Speed_FR/DCM_E_PENDING]
        arg OpStatus: type=Dcm_OpStatusType, direction=IN
        arg Data: type=Dcm_Data1ByteType, direction=OUT
      operation ConditionCheckRead: possible-error=[DataServices_Wheel_Speed_Wheel_Speed_FR/E_NOT_OK, DataServices_Wheel_Speed_Wheel_Speed_FR/DCM_E_PENDING]
        arg OpStatus: type=Dcm_OpStatusType, direction=IN
        arg ErrorCode: type=Dcm_NegativeResponseCodeType, direction=OUT
      error E_NOT_OK: error-code=1
      error DCM_E_PENDING: error-code=10
    DataServices_Wheel_Speed_Wheel_Voltage_RL
      operation ReadData: possible-error=[DataServices_Wheel_Speed_Wheel_Voltage_RL/E_NOT_OK, DataServices_Wheel_Speed_Wheel_Voltage_RL/DCM_E_PENDING]
        arg OpStatus: type=Dcm_OpStatusType, direction=IN
        arg Data: type=Dcm_Data1ByteType, direction=OUT
      operation ConditionCheckRead: possible-error=[DataServices_Wheel_Speed_Wheel_Voltage_RL/E_NOT_OK, DataServices_Wheel_Speed_Wheel_Voltage_RL/DCM_E_PENDING]
        arg OpStatus: type=Dcm_OpStatusType, direction=IN
        arg ErrorCode: type=Dcm_NegativeResponseCodeType, direction=OUT
      error E_NOT_OK: error-code=1
      error DCM_E_PENDING: error-code=10
    DataServices_Wheel_Speed_Wheel_Voltage_FR
      operation ReadData: possible-error=[DataServices_Wheel_Speed_Wheel_Voltage_FR/E_NOT_OK, DataServices_Wheel_Speed_Wheel_Voltage_FR/DCM_E_PENDING]
        arg OpStatus: type=Dcm_OpStatusType, direction=IN
        arg Data: type=Dcm_Data1ByteType, direction=OUT
      operation ConditionCheckRead: possible-error=[DataServices_Wheel_Speed_Wheel_Voltage_FR/E_NOT_OK, DataServices_Wheel_Speed_Wheel_Voltage_FR/DCM_E_PENDING]
        arg OpStatus: type=Dcm_OpStatusType, direction=IN
        arg ErrorCode: type=Dcm_NegativeResponseCodeType, direction=OUT
      error E_NOT_OK: error-code=1
      error DCM_E_PENDING: error-code=10
    DataServices_Wheel_Speed_Direction_of_rotation
      operation ReadData: possible-error=[DataServices_Wheel_Speed_Direction_of_rotation/E_NOT_OK, DataServices_Wheel_Speed_Direction_of_rotation/DCM_E_PENDING]
        arg OpStatus: type=Dcm_OpStatusType, direction=IN
        arg Data: type=Dcm_Data1ByteType, direction=OUT
      operation ConditionCheckRead: possible-error=[DataServices_Wheel_Speed_Direction_of_rotation/E_NOT_OK, DataServices_Wheel_Speed_Direction_of_rotation/DCM_E_PENDING]
        arg OpStatus: type=Dcm_OpStatusType, direction=IN
        arg ErrorCode: type=Dcm_NegativeResponseCodeType, direction=OUT
      error E_NOT_OK: error-code=1
      error DCM_E_PENDING: error-code=10
    DataServices_Wheel_Speed_Wheel_Voltage_FL
      operation ReadData: possible-error=[DataServices_Wheel_Speed_Wheel_Voltage_FL/E_NOT_OK, DataServices_Wheel_Speed_Wheel_Voltage_FL/DCM_E_PENDING]
        arg OpStatus: type=Dcm_OpStatusType, direction=IN
        arg Data: type=Dcm_Data1ByteType, direction=OUT
      operation ConditionCheckRead: possible-error=[DataServices_Wheel_Speed_Wheel_Voltage_FL/E_NOT_OK, DataServices_Wheel_Speed_Wheel_Voltage_FL/DCM_E_PENDING]
        arg OpStatus: type=Dcm_OpStatusType, direction=IN
        arg ErrorCode: type=Dcm_NegativeResponseCodeType, direction=OUT
      error E_NOT_OK: error-code=1
      error DCM_E_PENDING: error-code=10
    DataServices_Wheel_Speed_Wheel_Speed_RL
      operation ReadData: possible-error=[DataServices_Wheel_Speed_Wheel_Speed_RL/E_NOT_OK, DataServices_Wheel_Speed_Wheel_Speed_RL/DCM_E_PENDING]
        arg OpStatus: type=Dcm_OpStatusType, direction=IN
        arg Data: type=Dcm_Data1ByteType, direction=OUT
      operation ConditionCheckRead: possible-error=[DataServices_Wheel_Speed_Wheel_Speed_RL/E_NOT_OK, DataServices_Wheel_Speed_Wheel_Speed_RL/DCM_E_PENDING]
        arg OpStatus: type=Dcm_OpStatusType, direction=IN
        arg ErrorCode: type=Dcm_NegativeResponseCodeType, direction=OUT
      error E_NOT_OK: error-code=1
      error DCM_E_PENDING: error-code=10
    DataServices_Wheel_Speed_Wheel_Speed_FL
      operation ReadData: possible-error=[DataServices_Wheel_Speed_Wheel_Speed_FL/E_NOT_OK, DataServices_Wheel_Speed_Wheel_Speed_FL/DCM_E_PENDING]
        arg OpStatus: type=Dcm_OpStatusType, direction=IN
        arg Data: type=Dcm_Data1ByteType, direction=OUT
      operation ConditionCheckRead: possible-error=[DataServices_Wheel_Speed_Wheel_Speed_FL/E_NOT_OK, DataServices_Wheel_Speed_Wheel_Speed_FL/DCM_E_PENDING]
        arg OpStatus: type=Dcm_OpStatusType, direction=IN
        arg ErrorCode: type=Dcm_NegativeResponseCodeType, direction=OUT
      error E_NOT_OK: error-code=1
      error DCM_E_PENDING: error-code=10
    DataServices_Inflation_Pressure_Inflation_Pressure_FR
      operation ReadData: possible-error=[DataServices_Inflation_Pressure_Inflation_Pressure_FR/E_NOT_OK, DataServices_Inflation_Pressure_Inflation_Pressure_FR/DCM_E_PENDING]
        arg OpStatus: type=Dcm_OpStatusType, direction=IN
        arg Data: type=Dcm_Data1ByteType, direction=OUT
      operation ConditionCheckRead: possible-error=[DataServices_Inflation_Pressure_Inflation_Pressure_FR/E_NOT_OK, DataServices_Inflation_Pressure_Inflation_Pressure_FR/DCM_E_PENDING]
        arg OpStatus: type=Dcm_OpStatusType, direction=IN
        arg ErrorCode: type=Dcm_NegativeResponseCodeType, direction=OUT
      error E_NOT_OK: error-code=1
      error DCM_E_PENDING: error-code=10
    DataServices_Inflation_Pressure_Inflation_Pressure_RR
      operation ReadData: possible-error=[DataServices_Inflation_Pressure_Inflation_Pressure_RR/E_NOT_OK, DataServices_Inflation_Pressure_Inflation_Pressure_RR/DCM_E_PENDING]
        arg OpStatus: type=Dcm_OpStatusType, direction=IN
        arg Data: type=Dcm_Data1ByteType, direction=OUT
      operation ConditionCheckRead: possible-error=[DataServices_Inflation_Pressure_Inflation_Pressure_RR/E_NOT_OK, DataServices_Inflation_Pressure_Inflation_Pressure_RR/DCM_E_PENDING]
        arg OpStatus: type=Dcm_OpStatusType, direction=IN
        arg ErrorCode: type=Dcm_NegativeResponseCodeType, direction=OUT
      error E_NOT_OK: error-code=1
      error DCM_E_PENDING: error-code=10
    DataServices_Inflation_Pressure_Inflation_Pressure_FL
      operation ReadData: possible-error=[DataServices_Inflation_Pressure_Inflation_Pressure_FL/E_NOT_OK, DataServices_Inflation_Pressure_Inflation_Pressure_FL/DCM_E_PENDING]
        arg OpStatus: type=Dcm_OpStatusType, direction=IN
        arg Data: type=Dcm_Data1ByteType, direction=OUT
      operation ConditionCheckRead: possible-error=[DataServices_Inflation_Pressure_Inflation_Pressure_FL/E_NOT_OK, DataServices_Inflation_Pressure_Inflation_Pressure_FL/DCM_E_PENDING]
        arg OpStatus: type=Dcm_OpStatusType, direction=IN
        arg ErrorCode: type=Dcm_NegativeResponseCodeType, direction=OUT
      error E_NOT_OK: error-code=1
      error DCM_E_PENDING: error-code=10
    DataServices_Inflation_Pressure_Inflation_Pressure_RL
      operation ReadData: possible-error=[DataServices_Inflation_Pressure_Inflation_Pressure_RL/E_NOT_OK, DataServices_Inflation_Pressure_Inflation_Pressure_RL/DCM_E_PENDING]
        arg OpStatus: type=Dcm_OpStatusType, direction=IN
        arg Data: type=Dcm_Data1ByteType, direction=OUT
      operation ConditionCheckRead: possible-error=[DataServices_Inflation_Pressure_Inflation_Pressure_RL/E_NOT_OK, DataServices_Inflation_Pressure_Inflation_Pressure_RL/DCM_E_PENDING]
        arg OpStatus: type=Dcm_OpStatusType, direction=IN
        arg ErrorCode: type=Dcm_NegativeResponseCodeType, direction=OUT
      error E_NOT_OK: error-code=1
      error DCM_E_PENDING: error-code=10
    DataServices_Hardware_Part_Number_PartNumber
      operation ReadData: possible-error=[DataServices_Hardware_Part_Number_PartNumber/E_NOT_OK, DataServices_Hardware_Part_Number_PartNumber/DCM_E_PENDING]
        arg OpStatus: type=Dcm_OpStatusType, direction=IN
        arg Data: type=Dcm_Data13ByteType, direction=OUT
      operation ConditionCheckRead: possible-error=[DataServices_Hardware_Part_Number_PartNumber/E_NOT_OK, DataServices_Hardware_Part_Number_PartNumber/DCM_E_PENDING]
        arg OpStatus: type=Dcm_OpStatusType, direction=IN
        arg ErrorCode: type=Dcm_NegativeResponseCodeType, direction=OUT
      operation WriteData: possible-error=[DataServices_Hardware_Part_Number_PartNumber/E_NOT_OK, DataServices_Hardware_Part_Number_PartNumber/DCM_E_PENDING]
        arg Data: type=Dcm_Data13ByteType, direction=IN
        arg OpStatus: type=Dcm_OpStatusType, direction=IN
        arg ErrorCode: type=Dcm_NegativeResponseCodeType, direction=OUT
      error E_NOT_OK: error-code=1
      error DCM_E_PENDING: error-code=10
    DataServices_Acceleration_Sensor_Voltage
      operation ReadData: possible-error=[DataServices_Acceleration_Sensor_Voltage/E_NOT_OK, DataServices_Acceleration_Sensor_Voltage/DCM_E_PENDING]
        arg OpStatus: type=Dcm_OpStatusType, direction=IN
        arg Data: type=Dcm_Data1ByteType, direction=OUT
      operation ConditionCheckRead: possible-error=[DataServices_Acceleration_Sensor_Voltage/E_NOT_OK, DataServices_Acceleration_Sensor_Voltage/DCM_E_PENDING]
        arg OpStatus: type=Dcm_OpStatusType, direction=IN
        arg ErrorCode: type=Dcm_NegativeResponseCodeType, direction=OUT
      error E_NOT_OK: error-code=1
      error DCM_E_PENDING: error-code=10
    DataServices_Acceleration_Sensor_Acceleration
      operation ReadData: possible-error=[DataServices_Acceleration_Sensor_Acceleration/E_NOT_OK, DataServices_Acceleration_Sensor_Acceleration/DCM_E_PENDING]
        arg OpStatus: type=Dcm_OpStatusType, direction=IN
        arg Data: type=Dcm_Data1ByteType, direction=OUT
      operation ConditionCheckRead: possible-error=[DataServices_Acceleration_Sensor_Acceleration/E_NOT_OK, DataServices_Acceleration_Sensor_Acceleration/DCM_E_PENDING]
        arg OpStatus: type=Dcm_OpStatusType, direction=IN
        arg ErrorCode: type=Dcm_NegativeResponseCodeType, direction=OUT
      error E_NOT_OK: error-code=1
      error DCM_E_PENDING: error-code=10
    DataServices_Fingerprint_Repair_Shop_Identification
      operation ReadData: possible-error=[DataServices_Fingerprint_Repair_Shop_Identification/E_NOT_OK, DataServices_Fingerprint_Repair_Shop_Identification/DCM_E_PENDING]
        arg OpStatus: type=Dcm_OpStatusType, direction=IN
        arg Data: type=Dcm_Data1ByteType, direction=OUT
      operation ConditionCheckRead: possible-error=[DataServices_Fingerprint_Repair_Shop_Identification/E_NOT_OK, DataServices_Fingerprint_Repair_Shop_Identification/DCM_E_PENDING]
        arg OpStatus: type=Dcm_OpStatusType, direction=IN
        arg ErrorCode: type=Dcm_NegativeResponseCodeType, direction=OUT
      operation WriteData: possible-error=[DataServices_Fingerprint_Repair_Shop_Identification/E_NOT_OK, DataServices_Fingerprint_Repair_Shop_Identification/DCM_E_PENDING]
        arg Data: type=Dcm_Data1ByteType, direction=IN
        arg OpStatus: type=Dcm_OpStatusType, direction=IN
        arg ErrorCode: type=Dcm_NegativeResponseCodeType, direction=OUT
      error E_NOT_OK: error-code=1
      error DCM_E_PENDING: error-code=10
    DataServices_Fingerprint_Serial_number_of_flash_tool
      operation ReadData: possible-error=[DataServices_Fingerprint_Serial_number_of_flash_tool/E_NOT_OK, DataServices_Fingerprint_Serial_number_of_flash_tool/DCM_E_PENDING]
        arg OpStatus: type=Dcm_OpStatusType, direction=IN
        arg Data: type=Dcm_Data8ByteType, direction=OUT
      operation ConditionCheckRead: possible-error=[DataServices_Fingerprint_Serial_number_of_flash_tool/E_NOT_OK, DataServices_Fingerprint_Serial_number_of_flash_tool/DCM_E_PENDING]
        arg OpStatus: type=Dcm_OpStatusType, direction=IN
        arg ErrorCode: type=Dcm_NegativeResponseCodeType, direction=OUT
      operation WriteData: possible-error=[DataServices_Fingerprint_Serial_number_of_flash_tool/E_NOT_OK, DataServices_Fingerprint_Serial_number_of_flash_tool/DCM_E_PENDING]
        arg Data: type=Dcm_Data8ByteType, direction=IN
        arg OpStatus: type=Dcm_OpStatusType, direction=IN
        arg ErrorCode: type=Dcm_NegativeResponseCodeType, direction=OUT
      error E_NOT_OK: error-code=1
      error DCM_E_PENDING: error-code=10
    DataServices_Fingerprint_Programming_Date
      operation ReadData: possible-error=[DataServices_Fingerprint_Programming_Date/E_NOT_OK, DataServices_Fingerprint_Programming_Date/DCM_E_PENDING]
        arg OpStatus: type=Dcm_OpStatusType, direction=IN
        arg Data: type=Dcm_Data8ByteType, direction=OUT
      operation ConditionCheckRead: possible-error=[DataServices_Fingerprint_Programming_Date/E_NOT_OK, DataServices_Fingerprint_Programming_Date/DCM_E_PENDING]
        arg OpStatus: type=Dcm_OpStatusType, direction=IN
        arg ErrorCode: type=Dcm_NegativeResponseCodeType, direction=OUT
      operation WriteData: possible-error=[DataServices_Fingerprint_Programming_Date/E_NOT_OK, DataServices_Fingerprint_Programming_Date/DCM_E_PENDING]
        arg Data: type=Dcm_Data8ByteType, direction=IN
        arg OpStatus: type=Dcm_OpStatusType, direction=IN
        arg ErrorCode: type=Dcm_NegativeResponseCodeType, direction=OUT
      error E_NOT_OK: error-code=1
      error DCM_E_PENDING: error-code=10
    DataServices_Brake_Pedal_Valve_Status_RR
      operation ReadData: possible-error=[DataServices_Brake_Pedal_Valve_Status_RR/E_NOT_OK, DataServices_Brake_Pedal_Valve_Status_RR/DCM_E_PENDING]
        arg OpStatus: type=Dcm_OpStatusType, direction=IN
        arg Data: type=Dcm_Data1ByteType, direction=OUT
      operation ConditionCheckRead: possible-error=[DataServices_Brake_Pedal_Valve_Status_RR/E_NOT_OK, DataServices_Brake_Pedal_Valve_Status_RR/DCM_E_PENDING]
        arg OpStatus: type=Dcm_OpStatusType, direction=IN
        arg ErrorCode: type=Dcm_NegativeResponseCodeType, direction=OUT
      error E_NOT_OK: error-code=1
      error DCM_E_PENDING: error-code=10
    DataServices_Brake_Pedal_Valve_Voltage_FR
      operation ReadData: possible-error=[DataServices_Brake_Pedal_Valve_Voltage_FR/E_NOT_OK, DataServices_Brake_Pedal_Valve_Voltage_FR/DCM_E_PENDING]
        arg OpStatus: type=Dcm_OpStatusType, direction=IN
        arg Data: type=Dcm_Data1ByteType, direction=OUT
      operation ConditionCheckRead: possible-error=[DataServices_Brake_Pedal_Valve_Voltage_FR/E_NOT_OK, DataServices_Brake_Pedal_Valve_Voltage_FR/DCM_E_PENDING]
        arg OpStatus: type=Dcm_OpStatusType, direction=IN
        arg ErrorCode: type=Dcm_NegativeResponseCodeType, direction=OUT
      error E_NOT_OK: error-code=1
      error DCM_E_PENDING: error-code=10
    DataServices_Brake_Pedal_Valve_Status_FR
      operation ReadData: possible-error=[DataServices_Brake_Pedal_Valve_Status_FR/E_NOT_OK, DataServices_Brake_Pedal_Valve_Status_FR/DCM_E_PENDING]
        arg OpStatus: type=Dcm_OpStatusType, direction=IN
        arg Data: type=Dcm_Data1ByteType, direction=OUT
      operation ConditionCheckRead: possible-error=[DataServices_Brake_Pedal_Valve_Status_FR/E_NOT_OK, DataServices_Brake_Pedal_Valve_Status_FR/DCM_E_PENDING]
        arg OpStatus: type=Dcm_OpStatusType, direction=IN
        arg ErrorCode: type=Dcm_NegativeResponseCodeType, direction=OUT
      error E_NOT_OK: error-code=1
      error DCM_E_PENDING: error-code=10
    DataServices_Brake_Pedal_Valve_Voltage_RL
      operation ReadData: possible-error=[DataServices_Brake_Pedal_Valve_Voltage_RL/E_NOT_OK, DataServices_Brake_Pedal_Valve_Voltage_RL/DCM_E_PENDING]
        arg OpStatus: type=Dcm_OpStatusType, direction=IN
        arg Data: type=Dcm_Data1ByteType, direction=OUT
      operation ConditionCheckRead: possible-error=[DataServices_Brake_Pedal_Valve_Voltage_RL/E_NOT_OK, DataServices_Brake_Pedal_Valve_Voltage_RL/DCM_E_PENDING]
        arg OpStatus: type=Dcm_OpStatusType, direction=IN
        arg ErrorCode: type=Dcm_NegativeResponseCodeType, direction=OUT
      error E_NOT_OK: error-code=1
      error DCM_E_PENDING: error-code=10
    DataServices_Brake_Pedal_Valve_Status_RL
      operation ReadData: possible-error=[DataServices_Brake_Pedal_Valve_Status_RL/E_NOT_OK, DataServices_Brake_Pedal_Valve_Status_RL/DCM_E_PENDING]
        arg OpStatus: type=Dcm_OpStatusType, direction=IN
        arg Data: type=Dcm_Data1ByteType, direction=OUT
      operation ConditionCheckRead: possible-error=[DataServices_Brake_Pedal_Valve_Status_RL/E_NOT_OK, DataServices_Brake_Pedal_Valve_Status_RL/DCM_E_PENDING]
        arg OpStatus: type=Dcm_OpStatusType, direction=IN
        arg ErrorCode: type=Dcm_NegativeResponseCodeType, direction=OUT
      error E_NOT_OK: error-code=1
      error DCM_E_PENDING: error-code=10
    DataServices_Brake_Pedal_Valve_Voltage_FL
      operation ReadData: possible-error=[DataServices_Brake_Pedal_Valve_Voltage_FL/E_NOT_OK, DataServices_Brake_Pedal_Valve_Voltage_FL/DCM_E_PENDING]
        arg OpStatus: type=Dcm_OpStatusType, direction=IN
        arg Data: type=Dcm_Data1ByteType, direction=OUT
      operation ConditionCheckRead: possible-error=[DataServices_Brake_Pedal_Valve_Voltage_FL/E_NOT_OK, DataServices_Brake_Pedal_Valve_Voltage_FL/DCM_E_PENDING]
        arg OpStatus: type=Dcm_OpStatusType, direction=IN
        arg ErrorCode: type=Dcm_NegativeResponseCodeType, direction=OUT
      error E_NOT_OK: error-code=1
      error DCM_E_PENDING: error-code=10
    DataServices_Brake_Pedal_Valve_Voltage_RR
      operation ReadData: possible-error=[DataServices_Brake_Pedal_Valve_Voltage_RR/E_NOT_OK, DataServices_Brake_Pedal_Valve_Voltage_RR/DCM_E_PENDING]
        arg OpStatus: type=Dcm_OpStatusType, direction=IN
        arg Data: type=Dcm_Data1ByteType, direction=OUT
      operation ConditionCheckRead: possible-error=[DataServices_Brake_Pedal_Valve_Voltage_RR/E_NOT_OK, DataServices_Brake_Pedal_Valve_Voltage_RR/DCM_E_PENDING]
        arg OpStatus: type=Dcm_OpStatusType, direction=IN
        arg ErrorCode: type=Dcm_NegativeResponseCodeType, direction=OUT
      error E_NOT_OK: error-code=1
      error DCM_E_PENDING: error-code=10
    DataServices_Brake_Pedal_Valve_Status_FL
      operation ReadData: possible-error=[DataServices_Brake_Pedal_Valve_Status_FL/E_NOT_OK, DataServices_Brake_Pedal_Valve_Status_FL/DCM_E_PENDING]
        arg OpStatus: type=Dcm_OpStatusType, direction=IN
        arg Data: type=Dcm_Data1ByteType, direction=OUT
      operation ConditionCheckRead: possible-error=[DataServices_Brake_Pedal_Valve_Status_FL/E_NOT_OK, DataServices_Brake_Pedal_Valve_Status_FL/DCM_E_PENDING]
        arg OpStatus: type=Dcm_OpStatusType, direction=IN
        arg ErrorCode: type=Dcm_NegativeResponseCodeType, direction=OUT
      error E_NOT_OK: error-code=1
      error DCM_E_PENDING: error-code=10
    DataServices_Software_Supplier_Identification_SoftwareSupplier
      operation ReadData: possible-error=[DataServices_Software_Supplier_Identification_SoftwareSupplier/E_NOT_OK, DataServices_Software_Supplier_Identification_SoftwareSupplier/DCM_E_PENDING]
        arg OpStatus: type=Dcm_OpStatusType, direction=IN
        arg Data: type=Dcm_Data1ByteType, direction=OUT
      operation ConditionCheckRead: possible-error=[DataServices_Software_Supplier_Identification_SoftwareSupplier/E_NOT_OK, DataServices_Software_Supplier_Identification_SoftwareSupplier/DCM_E_PENDING]
        arg OpStatus: type=Dcm_OpStatusType, direction=IN
        arg ErrorCode: type=Dcm_NegativeResponseCodeType, direction=OUT
      operation WriteData: possible-error=[DataServices_Software_Supplier_Identification_SoftwareSupplier/E_NOT_OK, DataServices_Software_Supplier_Identification_SoftwareSupplier/DCM_E_PENDING]
        arg Data: type=Dcm_Data1ByteType, direction=IN
        arg OpStatus: type=Dcm_OpStatusType, direction=IN
        arg ErrorCode: type=Dcm_NegativeResponseCodeType, direction=OUT
      error E_NOT_OK: error-code=1
      error DCM_E_PENDING: error-code=10
    DataServices_Brake_Pressure_Brake_Pressure
      operation ReadData: possible-error=[DataServices_Brake_Pressure_Brake_Pressure/E_NOT_OK, DataServices_Brake_Pressure_Brake_Pressure/DCM_E_PENDING]
        arg OpStatus: type=Dcm_OpStatusType, direction=IN
        arg Data: type=Dcm_Data1ByteType, direction=OUT
      operation ConditionCheckRead: possible-error=[DataServices_Brake_Pressure_Brake_Pressure/E_NOT_OK, DataServices_Brake_Pressure_Brake_Pressure/DCM_E_PENDING]
        arg OpStatus: type=Dcm_OpStatusType, direction=IN
        arg ErrorCode: type=Dcm_NegativeResponseCodeType, direction=OUT
      error E_NOT_OK: error-code=1
      error DCM_E_PENDING: error-code=10
    DataServices_Supply_Voltage_ECU_Voltage_ECU
      operation ReadData: possible-error=[DataServices_Supply_Voltage_ECU_Voltage_ECU/E_NOT_OK, DataServices_Supply_Voltage_ECU_Voltage_ECU/DCM_E_PENDING]
        arg OpStatus: type=Dcm_OpStatusType, direction=IN
        arg Data: type=Dcm_Data1ByteType, direction=OUT
      operation ConditionCheckRead: possible-error=[DataServices_Supply_Voltage_ECU_Voltage_ECU/E_NOT_OK, DataServices_Supply_Voltage_ECU_Voltage_ECU/DCM_E_PENDING]
        arg OpStatus: type=Dcm_OpStatusType, direction=IN
        arg ErrorCode: type=Dcm_NegativeResponseCodeType, direction=OUT
      error E_NOT_OK: error-code=1
      error DCM_E_PENDING: error-code=10
package /MICROSAR/Dcm_swc/ComponentTypes
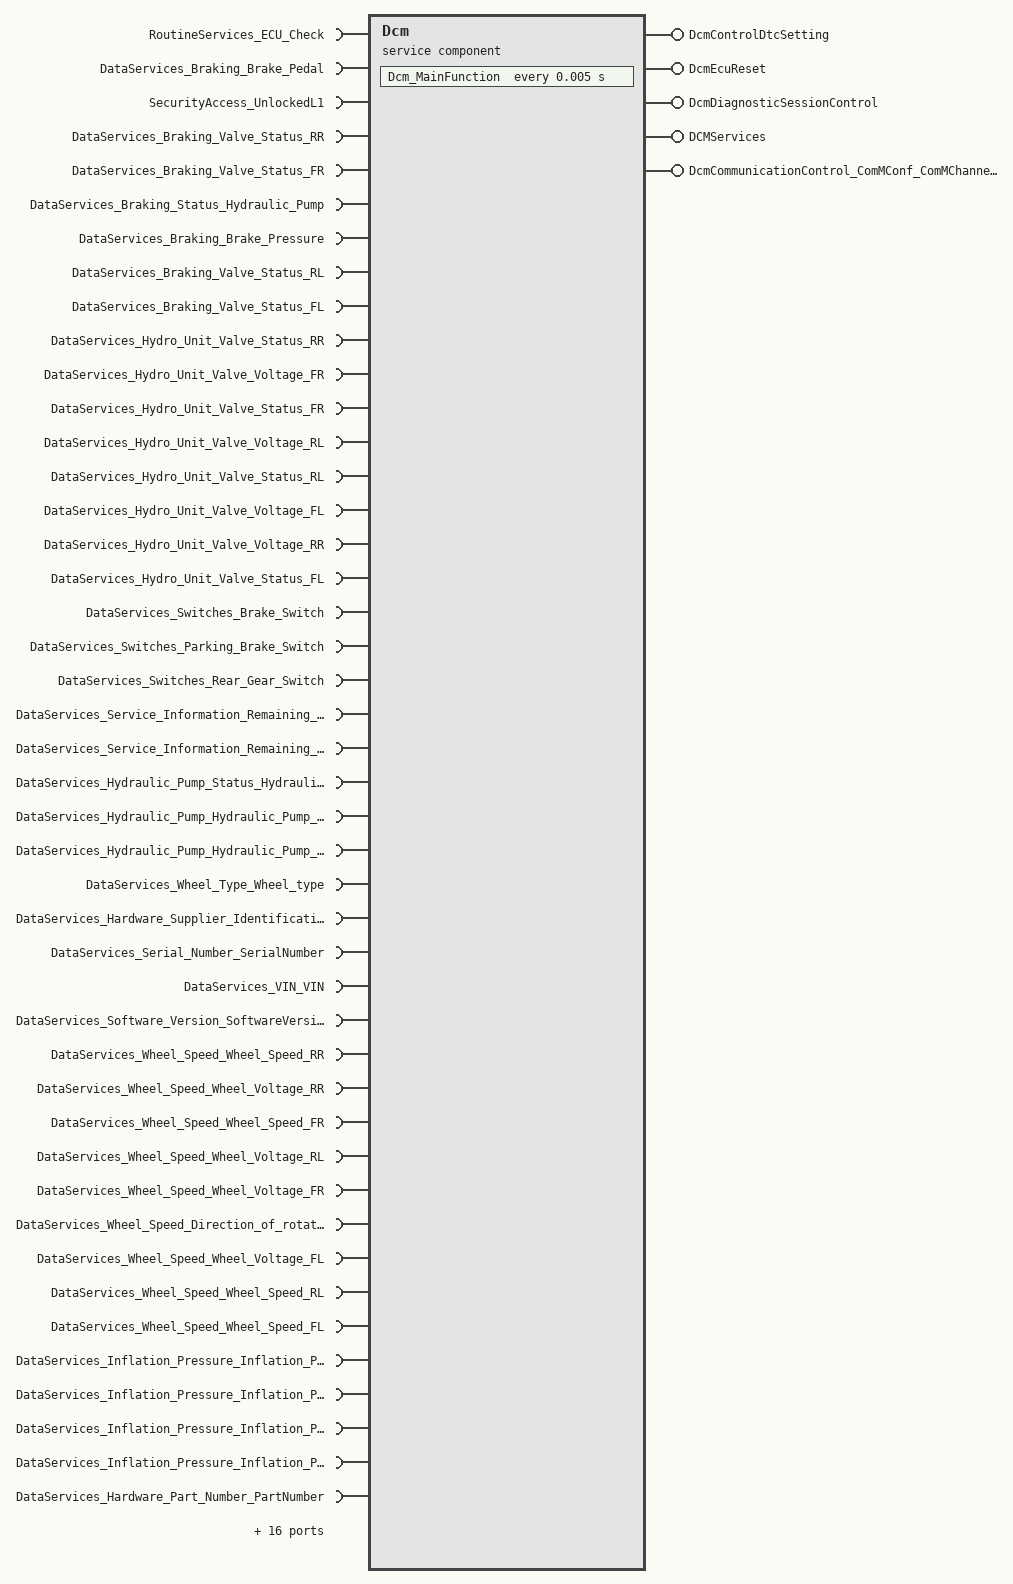
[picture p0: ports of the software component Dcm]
  service sw component type Dcm: category=SERVICE_COMPONENT
    4 x provide port:
      DcmControlDtcSetting: provided-interface=DcmControlDtcSetting
      DcmEcuReset: mode-switch-sender-com-spec{mode-group=DcmEcuReset, mode-switched-ack=timeout=0}, provided-interface=DcmEcuReset
      DcmDiagnosticSessionControl: provided-interface=DcmDiagnosticSessionControl
      DCMServices: provided-interface=DCMServices
    require port RoutineServices_ECU_Check: required-interface=RoutineServices_ECU_Check
    require port DataServices_Braking_Brake_Pedal: required-interface=DataServices_Braking_Brake_Pedal
    provide port DcmCommunicationControl_ComMConf_ComMChannel_CN_DBCNetWork_05d62413: provided-interface=DcmCommunicationControl_ComMConf_ComMChannel_CN_DBCNetWork_05d62413
    58 x require port:
      SecurityAccess_UnlockedL1: required-interface=SecurityAccess_UnlockedL1
      DataServices_Braking_Valve_Status_RR: required-interface=DataServices_Braking_Valve_Status_RR
      DataServices_Braking_Valve_Status_FR: required-interface=DataServices_Braking_Valve_Status_FR
      DataServices_Braking_Status_Hydraulic_Pump: required-interface=DataServices_Braking_Status_Hydraulic_Pump
      DataServices_Braking_Brake_Pressure: required-interface=DataServices_Braking_Brake_Pressure
      DataServices_Braking_Valve_Status_RL: required-interface=DataServices_Braking_Valve_Status_RL
      DataServices_Braking_Valve_Status_FL: required-interface=DataServices_Braking_Valve_Status_FL
      DataServices_Hydro_Unit_Valve_Status_RR: required-interface=DataServices_Hydro_Unit_Valve_Status_RR
      DataServices_Hydro_Unit_Valve_Voltage_FR: required-interface=DataServices_Hydro_Unit_Valve_Voltage_FR
      DataServices_Hydro_Unit_Valve_Status_FR: required-interface=DataServices_Hydro_Unit_Valve_Status_FR
      DataServices_Hydro_Unit_Valve_Voltage_RL: required-interface=DataServices_Hydro_Unit_Valve_Voltage_RL
      DataServices_Hydro_Unit_Valve_Status_RL: required-interface=DataServices_Hydro_Unit_Valve_Status_RL
      DataServices_Hydro_Unit_Valve_Voltage_FL: required-interface=DataServices_Hydro_Unit_Valve_Voltage_FL
      DataServices_Hydro_Unit_Valve_Voltage_RR: required-interface=DataServices_Hydro_Unit_Valve_Voltage_RR
      DataServices_Hydro_Unit_Valve_Status_FL: required-interface=DataServices_Hydro_Unit_Valve_Status_FL
      DataServices_Switches_Brake_Switch: required-interface=DataServices_Switches_Brake_Switch
      DataServices_Switches_Parking_Brake_Switch: required-interface=DataServices_Switches_Parking_Brake_Switch
      DataServices_Switches_Rear_Gear_Switch: required-interface=DataServices_Switches_Rear_Gear_Switch
      DataServices_Service_Information_Remaining_Service_Brake_Fluid_Life: required-interface=DataServices_Service_Information_Remaining_Service_Brake_Fluid_Life
      DataServices_Service_Information_Remaining_Service_Time_Left: required-interface=DataServices_Service_Information_Remaining_Service_Time_Left
      DataServices_Hydraulic_Pump_Status_Hydraulic_Pump: required-interface=DataServices_Hydraulic_Pump_Status_Hydraulic_Pump
      DataServices_Hydraulic_Pump_Hydraulic_Pump_Voltage: required-interface=DataServices_Hydraulic_Pump_Hydraulic_Pump_Voltage
      DataServices_Hydraulic_Pump_Hydraulic_Pump_Performance: required-interface=DataServices_Hydraulic_Pump_Hydraulic_Pump_Performance
      DataServices_Wheel_Type_Wheel_type: required-interface=DataServices_Wheel_Type_Wheel_type
      DataServices_Hardware_Supplier_Identification_HardwareSupplier: required-interface=DataServices_Hardware_Supplier_Identification_HardwareSupplier
      DataServices_Serial_Number_SerialNumber: required-interface=DataServices_Serial_Number_SerialNumber
      DataServices_VIN_VIN: required-interface=DataServices_VIN_VIN
      DataServices_Software_Version_SoftwareVersion: required-interface=DataServices_Software_Version_SoftwareVersion
      DataServices_Wheel_Speed_Wheel_Speed_RR: required-interface=DataServices_Wheel_Speed_Wheel_Speed_RR
      DataServices_Wheel_Speed_Wheel_Voltage_RR: required-interface=DataServices_Wheel_Speed_Wheel_Voltage_RR
      DataServices_Wheel_Speed_Wheel_Speed_FR: required-interface=DataServices_Wheel_Speed_Wheel_Speed_FR
      DataServices_Wheel_Speed_Wheel_Voltage_RL: required-interface=DataServices_Wheel_Speed_Wheel_Voltage_RL
      DataServices_Wheel_Speed_Wheel_Voltage_FR: required-interface=DataServices_Wheel_Speed_Wheel_Voltage_FR
      DataServices_Wheel_Speed_Direction_of_rotation: required-interface=DataServices_Wheel_Speed_Direction_of_rotation
      DataServices_Wheel_Speed_Wheel_Voltage_FL: required-interface=DataServices_Wheel_Speed_Wheel_Voltage_FL
      DataServices_Wheel_Speed_Wheel_Speed_RL: required-interface=DataServices_Wheel_Speed_Wheel_Speed_RL
      DataServices_Wheel_Speed_Wheel_Speed_FL: required-interface=DataServices_Wheel_Speed_Wheel_Speed_FL
      DataServices_Inflation_Pressure_Inflation_Pressure_FR: required-interface=DataServices_Inflation_Pressure_Inflation_Pressure_FR
      DataServices_Inflation_Pressure_Inflation_Pressure_RR: required-interface=DataServices_Inflation_Pressure_Inflation_Pressure_RR
      DataServices_Inflation_Pressure_Inflation_Pressure_FL: required-interface=DataServices_Inflation_Pressure_Inflation_Pressure_FL
      DataServices_Inflation_Pressure_Inflation_Pressure_RL: required-interface=DataServices_Inflation_Pressure_Inflation_Pressure_RL
      DataServices_Hardware_Part_Number_PartNumber: required-interface=DataServices_Hardware_Part_Number_PartNumber
      DataServices_Acceleration_Sensor_Voltage: required-interface=DataServices_Acceleration_Sensor_Voltage
      DataServices_Acceleration_Sensor_Acceleration: required-interface=DataServices_Acceleration_Sensor_Acceleration
      DataServices_Fingerprint_Repair_Shop_Identification: required-interface=DataServices_Fingerprint_Repair_Shop_Identification
      DataServices_Fingerprint_Serial_number_of_flash_tool: required-interface=DataServices_Fingerprint_Serial_number_of_flash_tool
      DataServices_Fingerprint_Programming_Date: required-interface=DataServices_Fingerprint_Programming_Date
      DataServices_Brake_Pedal_Valve_Status_RR: required-interface=DataServices_Brake_Pedal_Valve_Status_RR
      DataServices_Brake_Pedal_Valve_Voltage_FR: required-interface=DataServices_Brake_Pedal_Valve_Voltage_FR
      DataServices_Brake_Pedal_Valve_Status_FR: required-interface=DataServices_Brake_Pedal_Valve_Status_FR
      DataServices_Brake_Pedal_Valve_Voltage_RL: required-interface=DataServices_Brake_Pedal_Valve_Voltage_RL
      DataServices_Brake_Pedal_Valve_Status_RL: required-interface=DataServices_Brake_Pedal_Valve_Status_RL
      DataServices_Brake_Pedal_Valve_Voltage_FL: required-interface=DataServices_Brake_Pedal_Valve_Voltage_FL
      DataServices_Brake_Pedal_Valve_Voltage_RR: required-interface=DataServices_Brake_Pedal_Valve_Voltage_RR
      DataServices_Brake_Pedal_Valve_Status_FL: required-interface=DataServices_Brake_Pedal_Valve_Status_FL
      DataServices_Software_Supplier_Identification_SoftwareSupplier: required-interface=DataServices_Software_Supplier_Identification_SoftwareSupplier
      DataServices_Brake_Pressure_Brake_Pressure: required-interface=DataServices_Brake_Pressure_Brake_Pressure
      DataServices_Supply_Voltage_ECU_Voltage_ECU: required-interface=DataServices_Supply_Voltage_ECU_Voltage_ECU
    behavior DcmInternalBehavior: data-type-mapping=DcmMappingSet, handle-termination-and-restart=NO-SUPPORT, included-data-type-set=data-type=[Dcm_ConfirmationStatusType, Dcm_OpStatusType, Dcm_NegativeResponseCodeType, Dcm_ProtocolType, Dcm_RequestKindType, Dcm_SecLevelType, Dcm_SesCtrlType, Dcm_ControlDtcSettingType, Dcm_EcuResetType, Dcm_DiagnosticSessionControlType, Dcm_CommunicationModeType]
      timing event Timer_Dcm_MainFunction: start-on-event=Dcm_MainFunction, period=0.005
      6 x operation invoked event:
        OpEventGetActiveProtocol_GetActiveProtocol_DCMServices: start-on-event=GetActiveProtocol, operation=DCMServices.GetActiveProtocol
        OpEventGetSesCtrlType_GetSesCtrlType_DCMServices: start-on-event=GetSesCtrlType, operation=DCMServices.GetSesCtrlType
        OpEventResetToDefaultSession_ResetToDefaultSession_DCMServices: start-on-event=ResetToDefaultSession, operation=DCMServices.ResetToDefaultSession
        OpEventSetActiveDiagnostic_SetActiveDiagnostic_DCMServices: start-on-event=SetActiveDiagnostic, operation=DCMServices.SetActiveDiagnostic
        OpEventGetRequestKind_GetRequestKind_DCMServices: start-on-event=GetRequestKind, operation=DCMServices.GetRequestKind
        OpEventGetSecurityLevel_GetSecurityLevel_DCMServices: start-on-event=GetSecurityLevel, operation=DCMServices.GetSecurityLevel
      port-api-options:
        enable-take-address=true, indirect-api=false, port=DcmControlDtcSetting
        enable-take-address=true, indirect-api=false, port=DcmEcuReset
        enable-take-address=true, indirect-api=false, port=DcmDiagnosticSessionControl
        enable-take-address=true, indirect-api=false, port=DcmCommunicationControl_ComMConf_ComMChannel_CN_DBCNetWork_05d62413
        enable-take-address=true, indirect-api=false, port=DCMServices
        enable-take-address=true, indirect-api=false, port=SecurityAccess_UnlockedL1
        enable-take-address=true, indirect-api=false, port=RoutineServices_ECU_Check
        enable-take-address=true, indirect-api=false, port=DataServices_Braking_Brake_Pedal
        enable-take-address=true, indirect-api=false, port=DataServices_Braking_Valve_Status_RR
        enable-take-address=true, indirect-api=false, port=DataServices_Braking_Valve_Status_FR
        enable-take-address=true, indirect-api=false, port=DataServices_Braking_Status_Hydraulic_Pump
        enable-take-address=true, indirect-api=false, port=DataServices_Braking_Brake_Pressure
        enable-take-address=true, indirect-api=false, port=DataServices_Braking_Valve_Status_RL
        enable-take-address=true, indirect-api=false, port=DataServices_Braking_Valve_Status_FL
        enable-take-address=true, indirect-api=false, port=DataServices_Hydro_Unit_Valve_Status_RR
        enable-take-address=true, indirect-api=false, port=DataServices_Hydro_Unit_Valve_Voltage_FR
        enable-take-address=true, indirect-api=false, port=DataServices_Hydro_Unit_Valve_Status_FR
        enable-take-address=true, indirect-api=false, port=DataServices_Hydro_Unit_Valve_Voltage_RL
        enable-take-address=true, indirect-api=false, port=DataServices_Hydro_Unit_Valve_Status_RL
        enable-take-address=true, indirect-api=false, port=DataServices_Hydro_Unit_Valve_Voltage_FL
        enable-take-address=true, indirect-api=false, port=DataServices_Hydro_Unit_Valve_Voltage_RR
        enable-take-address=true, indirect-api=false, port=DataServices_Hydro_Unit_Valve_Status_FL
        enable-take-address=true, indirect-api=false, port=DataServices_Switches_Brake_Switch
        enable-take-address=true, indirect-api=false, port=DataServices_Switches_Parking_Brake_Switch
        enable-take-address=true, indirect-api=false, port=DataServices_Switches_Rear_Gear_Switch
        enable-take-address=true, indirect-api=false, port=DataServices_Service_Information_Remaining_Service_Brake_Fluid_Life
        enable-take-address=true, indirect-api=false, port=DataServices_Service_Information_Remaining_Service_Time_Left
        enable-take-address=true, indirect-api=false, port=DataServices_Hydraulic_Pump_Status_Hydraulic_Pump
        enable-take-address=true, indirect-api=false, port=DataServices_Hydraulic_Pump_Hydraulic_Pump_Voltage
        enable-take-address=true, indirect-api=false, port=DataServices_Hydraulic_Pump_Hydraulic_Pump_Performance
        enable-take-address=true, indirect-api=false, port=DataServices_Wheel_Type_Wheel_type
        enable-take-address=true, indirect-api=false, port=DataServices_Hardware_Supplier_Identification_HardwareSupplier
        enable-take-address=true, indirect-api=false, port=DataServices_Serial_Number_SerialNumber
        enable-take-address=true, indirect-api=false, port=DataServices_VIN_VIN
        enable-take-address=true, indirect-api=false, port=DataServices_Software_Version_SoftwareVersion
        enable-take-address=true, indirect-api=false, port=DataServices_Wheel_Speed_Wheel_Speed_RR
        enable-take-address=true, indirect-api=false, port=DataServices_Wheel_Speed_Wheel_Voltage_RR
        enable-take-address=true, indirect-api=false, port=DataServices_Wheel_Speed_Wheel_Speed_FR
        enable-take-address=true, indirect-api=false, port=DataServices_Wheel_Speed_Wheel_Voltage_RL
        enable-take-address=true, indirect-api=false, port=DataServices_Wheel_Speed_Wheel_Voltage_FR
        enable-take-address=true, indirect-api=false, port=DataServices_Wheel_Speed_Direction_of_rotation
        enable-take-address=true, indirect-api=false, port=DataServices_Wheel_Speed_Wheel_Voltage_FL
        enable-take-address=true, indirect-api=false, port=DataServices_Wheel_Speed_Wheel_Speed_RL
        enable-take-address=true, indirect-api=false, port=DataServices_Wheel_Speed_Wheel_Speed_FL
        enable-take-address=true, indirect-api=false, port=DataServices_Inflation_Pressure_Inflation_Pressure_FR
        enable-take-address=true, indirect-api=false, port=DataServices_Inflation_Pressure_Inflation_Pressure_RR
        enable-take-address=true, indirect-api=false, port=DataServices_Inflation_Pressure_Inflation_Pressure_FL
        enable-take-address=true, indirect-api=false, port=DataServices_Inflation_Pressure_Inflation_Pressure_RL
        enable-take-address=true, indirect-api=false, port=DataServices_Hardware_Part_Number_PartNumber
        enable-take-address=true, indirect-api=false, port=DataServices_Acceleration_Sensor_Voltage
        enable-take-address=true, indirect-api=false, port=DataServices_Acceleration_Sensor_Acceleration
        enable-take-address=true, indirect-api=false, port=DataServices_Fingerprint_Repair_Shop_Identification
        enable-take-address=true, indirect-api=false, port=DataServices_Fingerprint_Serial_number_of_flash_tool
        enable-take-address=true, indirect-api=false, port=DataServices_Fingerprint_Programming_Date
        enable-take-address=true, indirect-api=false, port=DataServices_Brake_Pedal_Valve_Status_RR
        enable-take-address=true, indirect-api=false, port=DataServices_Brake_Pedal_Valve_Voltage_FR
        enable-take-address=true, indirect-api=false, port=DataServices_Brake_Pedal_Valve_Status_FR
        enable-take-address=true, indirect-api=false, port=DataServices_Brake_Pedal_Valve_Voltage_RL
        enable-take-address=true, indirect-api=false, port=DataServices_Brake_Pedal_Valve_Status_RL
        enable-take-address=true, indirect-api=false, port=DataServices_Brake_Pedal_Valve_Voltage_FL
        enable-take-address=true, indirect-api=false, port=DataServices_Brake_Pedal_Valve_Voltage_RR
        enable-take-address=true, indirect-api=false, port=DataServices_Brake_Pedal_Valve_Status_FL
        enable-take-address=true, indirect-api=false, port=DataServices_Software_Supplier_Identification_SoftwareSupplier
        enable-take-address=true, indirect-api=false, port=DataServices_Brake_Pressure_Brake_Pressure
        enable-take-address=true, indirect-api=false, port=DataServices_Supply_Voltage_ECU_Voltage_ECU
      7 x runnable:
        Dcm_MainFunction
          4 x mode switch point:
            ModeSwitchPointDcm_MainFunction_DcmControlDtcSetting_DcmControlDtcSetting: mode-group=DcmControlDtcSetting.DcmControlDtcSetting
            ModeSwitchPointDcm_MainFunction_DcmEcuReset_DcmEcuReset: mode-group=DcmEcuReset.DcmEcuReset
            ModeSwitchPointDcm_MainFunction_DcmDiagnosticSessionControl_DcmDiagnosticSessionControl: mode-group=DcmDiagnosticSessionControl.DcmDiagnosticSessionControl
            ModeSwitchPointDcm_MainFunction_DcmCommunicationControl_ComMConf_ComMChannel_CN_DBCNetWork_05d62413_DcmCommunicationCon_10b5ec11: mode-group=DcmCommunicationControl_ComMConf_ComMChannel_CN_DBCNetWork_05d62413.DcmCommunicationControl_ComMConf_ComMChannel_CN_DBCNetWork_05d62413
          135 x sync call, all with timeout=0:
            OpServerCallDcm_MainFunction_Start_RoutineServices_ECU_Check: operation=RoutineServices_ECU_Check.Start
            OpServerCallDcm_MainFunction_RequestResults_RoutineServices_ECU_Check: operation=RoutineServices_ECU_Check.RequestResults
            OpServerCallDcm_MainFunction_ReadData_DataServices_Braking_Brake_Pedal: operation=DataServices_Braking_Brake_Pedal.ReadData
            OpServerCallDcm_MainFunction_ConditionCheckRead_DataServices_Braking_Brake_Pedal: operation=DataServices_Braking_Brake_Pedal.ConditionCheckRead
            OpServerCallDcm_MainFunction_GetSeed_SecurityAccess_UnlockedL1: operation=SecurityAccess_UnlockedL1.GetSeed
            OpServerCallDcm_MainFunction_CompareKey_SecurityAccess_UnlockedL1: operation=SecurityAccess_UnlockedL1.CompareKey
            OpServerCallDcm_MainFunction_ReadData_DataServices_Braking_Valve_Status_RR: operation=DataServices_Braking_Valve_Status_RR.ReadData
            OpServerCallDcm_MainFunction_ConditionCheckRead_DataServices_Braking_Valve_Status_RR: operation=DataServices_Braking_Valve_Status_RR.ConditionCheckRead
            OpServerCallDcm_MainFunction_ReadData_DataServices_Braking_Valve_Status_FR: operation=DataServices_Braking_Valve_Status_FR.ReadData
            OpServerCallDcm_MainFunction_ConditionCheckRead_DataServices_Braking_Valve_Status_FR: operation=DataServices_Braking_Valve_Status_FR.ConditionCheckRead
            OpServerCallDcm_MainFunction_ReadData_DataServices_Braking_Status_Hydraulic_Pump: operation=DataServices_Braking_Status_Hydraulic_Pump.ReadData
            OpServerCallDcm_MainFunction_ConditionCheckRead_DataServices_Braking_Status_Hydraulic_Pump: operation=DataServices_Braking_Status_Hydraulic_Pump.ConditionCheckRead
            OpServerCallDcm_MainFunction_ReadData_DataServices_Braking_Brake_Pressure: operation=DataServices_Braking_Brake_Pressure.ReadData
            OpServerCallDcm_MainFunction_ConditionCheckRead_DataServices_Braking_Brake_Pressure: operation=DataServices_Braking_Brake_Pressure.ConditionCheckRead
            OpServerCallDcm_MainFunction_ReadData_DataServices_Braking_Valve_Status_RL: operation=DataServices_Braking_Valve_Status_RL.ReadData
            OpServerCallDcm_MainFunction_ConditionCheckRead_DataServices_Braking_Valve_Status_RL: operation=DataServices_Braking_Valve_Status_RL.ConditionCheckRead
            OpServerCallDcm_MainFunction_ReadData_DataServices_Braking_Valve_Status_FL: operation=DataServices_Braking_Valve_Status_FL.ReadData
            OpServerCallDcm_MainFunction_ConditionCheckRead_DataServices_Braking_Valve_Status_FL: operation=DataServices_Braking_Valve_Status_FL.ConditionCheckRead
            OpServerCallDcm_MainFunction_ReadData_DataServices_Hydro_Unit_Valve_Status_RR: operation=DataServices_Hydro_Unit_Valve_Status_RR.ReadData
            OpServerCallDcm_MainFunction_ConditionCheckRead_DataServices_Hydro_Unit_Valve_Status_RR: operation=DataServices_Hydro_Unit_Valve_Status_RR.ConditionCheckRead
            OpServerCallDcm_MainFunction_ReadData_DataServices_Hydro_Unit_Valve_Voltage_FR: operation=DataServices_Hydro_Unit_Valve_Voltage_FR.ReadData
            OpServerCallDcm_MainFunction_ConditionCheckRead_DataServices_Hydro_Unit_Valve_Voltage_FR: operation=DataServices_Hydro_Unit_Valve_Voltage_FR.ConditionCheckRead
            OpServerCallDcm_MainFunction_ReadData_DataServices_Hydro_Unit_Valve_Status_FR: operation=DataServices_Hydro_Unit_Valve_Status_FR.ReadData
            OpServerCallDcm_MainFunction_ConditionCheckRead_DataServices_Hydro_Unit_Valve_Status_FR: operation=DataServices_Hydro_Unit_Valve_Status_FR.ConditionCheckRead
            OpServerCallDcm_MainFunction_ReadData_DataServices_Hydro_Unit_Valve_Voltage_RL: operation=DataServices_Hydro_Unit_Valve_Voltage_RL.ReadData
            OpServerCallDcm_MainFunction_ConditionCheckRead_DataServices_Hydro_Unit_Valve_Voltage_RL: operation=DataServices_Hydro_Unit_Valve_Voltage_RL.ConditionCheckRead
            OpServerCallDcm_MainFunction_ReadData_DataServices_Hydro_Unit_Valve_Status_RL: operation=DataServices_Hydro_Unit_Valve_Status_RL.ReadData
            OpServerCallDcm_MainFunction_ConditionCheckRead_DataServices_Hydro_Unit_Valve_Status_RL: operation=DataServices_Hydro_Unit_Valve_Status_RL.ConditionCheckRead
            OpServerCallDcm_MainFunction_ReadData_DataServices_Hydro_Unit_Valve_Voltage_FL: operation=DataServices_Hydro_Unit_Valve_Voltage_FL.ReadData
            OpServerCallDcm_MainFunction_ConditionCheckRead_DataServices_Hydro_Unit_Valve_Voltage_FL: operation=DataServices_Hydro_Unit_Valve_Voltage_FL.ConditionCheckRead
            OpServerCallDcm_MainFunction_ReadData_DataServices_Hydro_Unit_Valve_Voltage_RR: operation=DataServices_Hydro_Unit_Valve_Voltage_RR.ReadData
            OpServerCallDcm_MainFunction_ConditionCheckRead_DataServices_Hydro_Unit_Valve_Voltage_RR: operation=DataServices_Hydro_Unit_Valve_Voltage_RR.ConditionCheckRead
            OpServerCallDcm_MainFunction_ReadData_DataServices_Hydro_Unit_Valve_Status_FL: operation=DataServices_Hydro_Unit_Valve_Status_FL.ReadData
            OpServerCallDcm_MainFunction_ConditionCheckRead_DataServices_Hydro_Unit_Valve_Status_FL: operation=DataServices_Hydro_Unit_Valve_Status_FL.ConditionCheckRead
            OpServerCallDcm_MainFunction_ReadData_DataServices_Switches_Brake_Switch: operation=DataServices_Switches_Brake_Switch.ReadData
            OpServerCallDcm_MainFunction_ResetToDefault_DataServices_Switches_Brake_Switch: operation=DataServices_Switches_Brake_Switch.ResetToDefault
            OpServerCallDcm_MainFunction_ShortTermAdjustment_DataServices_Switches_Brake_Switch: operation=DataServices_Switches_Brake_Switch.ShortTermAdjustment
            OpServerCallDcm_MainFunction_ReadData_DataServices_Switches_Parking_Brake_Switch: operation=DataServices_Switches_Parking_Brake_Switch.ReadData
            OpServerCallDcm_MainFunction_ResetToDefault_DataServices_Switches_Parking_Brake_Switch: operation=DataServices_Switches_Parking_Brake_Switch.ResetToDefault
            OpServerCallDcm_MainFunction_ShortTermAdjustment_DataServices_Switches_Parking_Brake_Switch: operation=DataServices_Switches_Parking_Brake_Switch.ShortTermAdjustment
            OpServerCallDcm_MainFunction_ReadData_DataServices_Switches_Rear_Gear_Switch: operation=DataServices_Switches_Rear_Gear_Switch.ReadData
            OpServerCallDcm_MainFunction_ResetToDefault_DataServices_Switches_Rear_Gear_Switch: operation=DataServices_Switches_Rear_Gear_Switch.ResetToDefault
            OpServerCallDcm_MainFunction_ShortTermAdjustment_DataServices_Switches_Rear_Gear_Switch: operation=DataServices_Switches_Rear_Gear_Switch.ShortTermAdjustment
            OpServerCallDcm_MainFunction_ReadData_DataServices_Service_Information_Remaining_Service_Brake_Fluid_Life: operation=DataServices_Service_Information_Remaining_Service_Brake_Fluid_Life.ReadData
            OpServerCallDcm_MainFunction_ConditionCheckRead_DataServices_Service_Information_Remaining_Service_Brake_Fluid_Life: operation=DataServices_Service_Information_Remaining_Service_Brake_Fluid_Life.ConditionCheckRead
            OpServerCallDcm_MainFunction_WriteData_DataServices_Service_Information_Remaining_Service_Brake_Fluid_Life: operation=DataServices_Service_Information_Remaining_Service_Brake_Fluid_Life.WriteData
            OpServerCallDcm_MainFunction_ReadData_DataServices_Service_Information_Remaining_Service_Time_Left: operation=DataServices_Service_Information_Remaining_Service_Time_Left.ReadData
            OpServerCallDcm_MainFunction_ConditionCheckRead_DataServices_Service_Information_Remaining_Service_Time_Left: operation=DataServices_Service_Information_Remaining_Service_Time_Left.ConditionCheckRead
            OpServerCallDcm_MainFunction_WriteData_DataServices_Service_Information_Remaining_Service_Time_Left: operation=DataServices_Service_Information_Remaining_Service_Time_Left.WriteData
            OpServerCallDcm_MainFunction_ReadData_DataServices_Hydraulic_Pump_Status_Hydraulic_Pump: operation=DataServices_Hydraulic_Pump_Status_Hydraulic_Pump.ReadData
            OpServerCallDcm_MainFunction_ConditionCheckRead_DataServices_Hydraulic_Pump_Status_Hydraulic_Pump: operation=DataServices_Hydraulic_Pump_Status_Hydraulic_Pump.ConditionCheckRead
            OpServerCallDcm_MainFunction_ReadData_DataServices_Hydraulic_Pump_Hydraulic_Pump_Voltage: operation=DataServices_Hydraulic_Pump_Hydraulic_Pump_Voltage.ReadData
            OpServerCallDcm_MainFunction_ConditionCheckRead_DataServices_Hydraulic_Pump_Hydraulic_Pump_Voltage: operation=DataServices_Hydraulic_Pump_Hydraulic_Pump_Voltage.ConditionCheckRead
            OpServerCallDcm_MainFunction_ReadData_DataServices_Hydraulic_Pump_Hydraulic_Pump_Performance: operation=DataServices_Hydraulic_Pump_Hydraulic_Pump_Performance.ReadData
            OpServerCallDcm_MainFunction_ConditionCheckRead_DataServices_Hydraulic_Pump_Hydraulic_Pump_Performance: operation=DataServices_Hydraulic_Pump_Hydraulic_Pump_Performance.ConditionCheckRead
            OpServerCallDcm_MainFunction_ReadData_DataServices_Wheel_Type_Wheel_type: operation=DataServices_Wheel_Type_Wheel_type.ReadData
            OpServerCallDcm_MainFunction_ConditionCheckRead_DataServices_Wheel_Type_Wheel_type: operation=DataServices_Wheel_Type_Wheel_type.ConditionCheckRead
            OpServerCallDcm_MainFunction_WriteData_DataServices_Wheel_Type_Wheel_type: operation=DataServices_Wheel_Type_Wheel_type.WriteData
            OpServerCallDcm_MainFunction_ReadData_DataServices_Hardware_Supplier_Identification_HardwareSupplier: operation=DataServices_Hardware_Supplier_Identification_HardwareSupplier.ReadData
            OpServerCallDcm_MainFunction_ConditionCheckRead_DataServices_Hardware_Supplier_Identification_HardwareSupplier: operation=DataServices_Hardware_Supplier_Identification_HardwareSupplier.ConditionCheckRead
            OpServerCallDcm_MainFunction_WriteData_DataServices_Hardware_Supplier_Identification_HardwareSupplier: operation=DataServices_Hardware_Supplier_Identification_HardwareSupplier.WriteData
            OpServerCallDcm_MainFunction_ReadData_DataServices_Serial_Number_SerialNumber: operation=DataServices_Serial_Number_SerialNumber.ReadData
            OpServerCallDcm_MainFunction_ConditionCheckRead_DataServices_Serial_Number_SerialNumber: operation=DataServices_Serial_Number_SerialNumber.ConditionCheckRead
            OpServerCallDcm_MainFunction_WriteData_DataServices_Serial_Number_SerialNumber: operation=DataServices_Serial_Number_SerialNumber.WriteData
            OpServerCallDcm_MainFunction_ReadData_DataServices_VIN_VIN: operation=DataServices_VIN_VIN.ReadData
            OpServerCallDcm_MainFunction_ConditionCheckRead_DataServices_VIN_VIN: operation=DataServices_VIN_VIN.ConditionCheckRead
            OpServerCallDcm_MainFunction_WriteData_DataServices_VIN_VIN: operation=DataServices_VIN_VIN.WriteData
            OpServerCallDcm_MainFunction_ReadData_DataServices_Software_Version_SoftwareVersion: operation=DataServices_Software_Version_SoftwareVersion.ReadData
            OpServerCallDcm_MainFunction_ConditionCheckRead_DataServices_Software_Version_SoftwareVersion: operation=DataServices_Software_Version_SoftwareVersion.ConditionCheckRead
            OpServerCallDcm_MainFunction_WriteData_DataServices_Software_Version_SoftwareVersion: operation=DataServices_Software_Version_SoftwareVersion.WriteData
            OpServerCallDcm_MainFunction_ReadData_DataServices_Wheel_Speed_Wheel_Speed_RR: operation=DataServices_Wheel_Speed_Wheel_Speed_RR.ReadData
            OpServerCallDcm_MainFunction_ConditionCheckRead_DataServices_Wheel_Speed_Wheel_Speed_RR: operation=DataServices_Wheel_Speed_Wheel_Speed_RR.ConditionCheckRead
            OpServerCallDcm_MainFunction_ReadData_DataServices_Wheel_Speed_Wheel_Voltage_RR: operation=DataServices_Wheel_Speed_Wheel_Voltage_RR.ReadData
            OpServerCallDcm_MainFunction_ConditionCheckRead_DataServices_Wheel_Speed_Wheel_Voltage_RR: operation=DataServices_Wheel_Speed_Wheel_Voltage_RR.ConditionCheckRead
            OpServerCallDcm_MainFunction_ReadData_DataServices_Wheel_Speed_Wheel_Speed_FR: operation=DataServices_Wheel_Speed_Wheel_Speed_FR.ReadData
            OpServerCallDcm_MainFunction_ConditionCheckRead_DataServices_Wheel_Speed_Wheel_Speed_FR: operation=DataServices_Wheel_Speed_Wheel_Speed_FR.ConditionCheckRead
            OpServerCallDcm_MainFunction_ReadData_DataServices_Wheel_Speed_Wheel_Voltage_RL: operation=DataServices_Wheel_Speed_Wheel_Voltage_RL.ReadData
            OpServerCallDcm_MainFunction_ConditionCheckRead_DataServices_Wheel_Speed_Wheel_Voltage_RL: operation=DataServices_Wheel_Speed_Wheel_Voltage_RL.ConditionCheckRead
            OpServerCallDcm_MainFunction_ReadData_DataServices_Wheel_Speed_Wheel_Voltage_FR: operation=DataServices_Wheel_Speed_Wheel_Voltage_FR.ReadData
            OpServerCallDcm_MainFunction_ConditionCheckRead_DataServices_Wheel_Speed_Wheel_Voltage_FR: operation=DataServices_Wheel_Speed_Wheel_Voltage_FR.ConditionCheckRead
            OpServerCallDcm_MainFunction_ReadData_DataServices_Wheel_Speed_Direction_of_rotation: operation=DataServices_Wheel_Speed_Direction_of_rotation.ReadData
            OpServerCallDcm_MainFunction_ConditionCheckRead_DataServices_Wheel_Speed_Direction_of_rotation: operation=DataServices_Wheel_Speed_Direction_of_rotation.ConditionCheckRead
            OpServerCallDcm_MainFunction_ReadData_DataServices_Wheel_Speed_Wheel_Voltage_FL: operation=DataServices_Wheel_Speed_Wheel_Voltage_FL.ReadData
            OpServerCallDcm_MainFunction_ConditionCheckRead_DataServices_Wheel_Speed_Wheel_Voltage_FL: operation=DataServices_Wheel_Speed_Wheel_Voltage_FL.ConditionCheckRead
            OpServerCallDcm_MainFunction_ReadData_DataServices_Wheel_Speed_Wheel_Speed_RL: operation=DataServices_Wheel_Speed_Wheel_Speed_RL.ReadData
            OpServerCallDcm_MainFunction_ConditionCheckRead_DataServices_Wheel_Speed_Wheel_Speed_RL: operation=DataServices_Wheel_Speed_Wheel_Speed_RL.ConditionCheckRead
            OpServerCallDcm_MainFunction_ReadData_DataServices_Wheel_Speed_Wheel_Speed_FL: operation=DataServices_Wheel_Speed_Wheel_Speed_FL.ReadData
            OpServerCallDcm_MainFunction_ConditionCheckRead_DataServices_Wheel_Speed_Wheel_Speed_FL: operation=DataServices_Wheel_Speed_Wheel_Speed_FL.ConditionCheckRead
            OpServerCallDcm_MainFunction_ReadData_DataServices_Inflation_Pressure_Inflation_Pressure_FR: operation=DataServices_Inflation_Pressure_Inflation_Pressure_FR.ReadData
            OpServerCallDcm_MainFunction_ConditionCheckRead_DataServices_Inflation_Pressure_Inflation_Pressure_FR: operation=DataServices_Inflation_Pressure_Inflation_Pressure_FR.ConditionCheckRead
            OpServerCallDcm_MainFunction_ReadData_DataServices_Inflation_Pressure_Inflation_Pressure_RR: operation=DataServices_Inflation_Pressure_Inflation_Pressure_RR.ReadData
            OpServerCallDcm_MainFunction_ConditionCheckRead_DataServices_Inflation_Pressure_Inflation_Pressure_RR: operation=DataServices_Inflation_Pressure_Inflation_Pressure_RR.ConditionCheckRead
            OpServerCallDcm_MainFunction_ReadData_DataServices_Inflation_Pressure_Inflation_Pressure_FL: operation=DataServices_Inflation_Pressure_Inflation_Pressure_FL.ReadData
            OpServerCallDcm_MainFunction_ConditionCheckRead_DataServices_Inflation_Pressure_Inflation_Pressure_FL: operation=DataServices_Inflation_Pressure_Inflation_Pressure_FL.ConditionCheckRead
            OpServerCallDcm_MainFunction_ReadData_DataServices_Inflation_Pressure_Inflation_Pressure_RL: operation=DataServices_Inflation_Pressure_Inflation_Pressure_RL.ReadData
            OpServerCallDcm_MainFunction_ConditionCheckRead_DataServices_Inflation_Pressure_Inflation_Pressure_RL: operation=DataServices_Inflation_Pressure_Inflation_Pressure_RL.ConditionCheckRead
            OpServerCallDcm_MainFunction_ReadData_DataServices_Hardware_Part_Number_PartNumber: operation=DataServices_Hardware_Part_Number_PartNumber.ReadData
            OpServerCallDcm_MainFunction_ConditionCheckRead_DataServices_Hardware_Part_Number_PartNumber: operation=DataServices_Hardware_Part_Number_PartNumber.ConditionCheckRead
            OpServerCallDcm_MainFunction_WriteData_DataServices_Hardware_Part_Number_PartNumber: operation=DataServices_Hardware_Part_Number_PartNumber.WriteData
            OpServerCallDcm_MainFunction_ReadData_DataServices_Acceleration_Sensor_Voltage: operation=DataServices_Acceleration_Sensor_Voltage.ReadData
            OpServerCallDcm_MainFunction_ConditionCheckRead_DataServices_Acceleration_Sensor_Voltage: operation=DataServices_Acceleration_Sensor_Voltage.ConditionCheckRead
            OpServerCallDcm_MainFunction_ReadData_DataServices_Acceleration_Sensor_Acceleration: operation=DataServices_Acceleration_Sensor_Acceleration.ReadData
            OpServerCallDcm_MainFunction_ConditionCheckRead_DataServices_Acceleration_Sensor_Acceleration: operation=DataServices_Acceleration_Sensor_Acceleration.ConditionCheckRead
            OpServerCallDcm_MainFunction_ReadData_DataServices_Fingerprint_Repair_Shop_Identification: operation=DataServices_Fingerprint_Repair_Shop_Identification.ReadData
            OpServerCallDcm_MainFunction_ConditionCheckRead_DataServices_Fingerprint_Repair_Shop_Identification: operation=DataServices_Fingerprint_Repair_Shop_Identification.ConditionCheckRead
            OpServerCallDcm_MainFunction_WriteData_DataServices_Fingerprint_Repair_Shop_Identification: operation=DataServices_Fingerprint_Repair_Shop_Identification.WriteData
            OpServerCallDcm_MainFunction_ReadData_DataServices_Fingerprint_Serial_number_of_flash_tool: operation=DataServices_Fingerprint_Serial_number_of_flash_tool.ReadData
            OpServerCallDcm_MainFunction_ConditionCheckRead_DataServices_Fingerprint_Serial_number_of_flash_tool: operation=DataServices_Fingerprint_Serial_number_of_flash_tool.ConditionCheckRead
            OpServerCallDcm_MainFunction_WriteData_DataServices_Fingerprint_Serial_number_of_flash_tool: operation=DataServices_Fingerprint_Serial_number_of_flash_tool.WriteData
            OpServerCallDcm_MainFunction_ReadData_DataServices_Fingerprint_Programming_Date: operation=DataServices_Fingerprint_Programming_Date.ReadData
            OpServerCallDcm_MainFunction_ConditionCheckRead_DataServices_Fingerprint_Programming_Date: operation=DataServices_Fingerprint_Programming_Date.ConditionCheckRead
            OpServerCallDcm_MainFunction_WriteData_DataServices_Fingerprint_Programming_Date: operation=DataServices_Fingerprint_Programming_Date.WriteData
            OpServerCallDcm_MainFunction_ReadData_DataServices_Brake_Pedal_Valve_Status_RR: operation=DataServices_Brake_Pedal_Valve_Status_RR.ReadData
            OpServerCallDcm_MainFunction_ConditionCheckRead_DataServices_Brake_Pedal_Valve_Status_RR: operation=DataServices_Brake_Pedal_Valve_Status_RR.ConditionCheckRead
            OpServerCallDcm_MainFunction_ReadData_DataServices_Brake_Pedal_Valve_Voltage_FR: operation=DataServices_Brake_Pedal_Valve_Voltage_FR.ReadData
            OpServerCallDcm_MainFunction_ConditionCheckRead_DataServices_Brake_Pedal_Valve_Voltage_FR: operation=DataServices_Brake_Pedal_Valve_Voltage_FR.ConditionCheckRead
            OpServerCallDcm_MainFunction_ReadData_DataServices_Brake_Pedal_Valve_Status_FR: operation=DataServices_Brake_Pedal_Valve_Status_FR.ReadData
            OpServerCallDcm_MainFunction_ConditionCheckRead_DataServices_Brake_Pedal_Valve_Status_FR: operation=DataServices_Brake_Pedal_Valve_Status_FR.ConditionCheckRead
            OpServerCallDcm_MainFunction_ReadData_DataServices_Brake_Pedal_Valve_Voltage_RL: operation=DataServices_Brake_Pedal_Valve_Voltage_RL.ReadData
            OpServerCallDcm_MainFunction_ConditionCheckRead_DataServices_Brake_Pedal_Valve_Voltage_RL: operation=DataServices_Brake_Pedal_Valve_Voltage_RL.ConditionCheckRead
            OpServerCallDcm_MainFunction_ReadData_DataServices_Brake_Pedal_Valve_Status_RL: operation=DataServices_Brake_Pedal_Valve_Status_RL.ReadData
            OpServerCallDcm_MainFunction_ConditionCheckRead_DataServices_Brake_Pedal_Valve_Status_RL: operation=DataServices_Brake_Pedal_Valve_Status_RL.ConditionCheckRead
            OpServerCallDcm_MainFunction_ReadData_DataServices_Brake_Pedal_Valve_Voltage_FL: operation=DataServices_Brake_Pedal_Valve_Voltage_FL.ReadData
            OpServerCallDcm_MainFunction_ConditionCheckRead_DataServices_Brake_Pedal_Valve_Voltage_FL: operation=DataServices_Brake_Pedal_Valve_Voltage_FL.ConditionCheckRead
            OpServerCallDcm_MainFunction_ReadData_DataServices_Brake_Pedal_Valve_Voltage_RR: operation=DataServices_Brake_Pedal_Valve_Voltage_RR.ReadData
            OpServerCallDcm_MainFunction_ConditionCheckRead_DataServices_Brake_Pedal_Valve_Voltage_RR: operation=DataServices_Brake_Pedal_Valve_Voltage_RR.ConditionCheckRead
            OpServerCallDcm_MainFunction_ReadData_DataServices_Brake_Pedal_Valve_Status_FL: operation=DataServices_Brake_Pedal_Valve_Status_FL.ReadData
            OpServerCallDcm_MainFunction_ConditionCheckRead_DataServices_Brake_Pedal_Valve_Status_FL: operation=DataServices_Brake_Pedal_Valve_Status_FL.ConditionCheckRead
            OpServerCallDcm_MainFunction_ReadData_DataServices_Software_Supplier_Identification_SoftwareSupplier: operation=DataServices_Software_Supplier_Identification_SoftwareSupplier.ReadData
            OpServerCallDcm_MainFunction_ConditionCheckRead_DataServices_Software_Supplier_Identification_SoftwareSupplier: operation=DataServices_Software_Supplier_Identification_SoftwareSupplier.ConditionCheckRead
            OpServerCallDcm_MainFunction_WriteData_DataServices_Software_Supplier_Identification_SoftwareSupplier: operation=DataServices_Software_Supplier_Identification_SoftwareSupplier.WriteData
            OpServerCallDcm_MainFunction_ReadData_DataServices_Brake_Pressure_Brake_Pressure: operation=DataServices_Brake_Pressure_Brake_Pressure.ReadData
            OpServerCallDcm_MainFunction_ConditionCheckRead_DataServices_Brake_Pressure_Brake_Pressure: operation=DataServices_Brake_Pressure_Brake_Pressure.ConditionCheckRead
            OpServerCallDcm_MainFunction_ReadData_DataServices_Supply_Voltage_ECU_Voltage_ECU: operation=DataServices_Supply_Voltage_ECU_Voltage_ECU.ReadData
            OpServerCallDcm_MainFunction_ConditionCheckRead_DataServices_Supply_Voltage_ECU_Voltage_ECU: operation=DataServices_Supply_Voltage_ECU_Voltage_ECU.ConditionCheckRead
        GetActiveProtocol: can-be-invoked-concurrently=true, symbol=Dcm_GetActiveProtocol
        GetSesCtrlType: can-be-invoked-concurrently=true, symbol=Dcm_GetSesCtrlType
        ResetToDefaultSession: can-be-invoked-concurrently=true, symbol=Dcm_ResetToDefaultSession
        SetActiveDiagnostic: can-be-invoked-concurrently=true, symbol=Dcm_SetActiveDiagnostic
        GetRequestKind: can-be-invoked-concurrently=true, symbol=Dcm_GetRequestKind
        GetSecurityLevel: can-be-invoked-concurrently=true, symbol=Dcm_GetSecurityLevel
  swc implementation DcmImplementation: programming-language=C, behavior=DcmInternalBehavior
